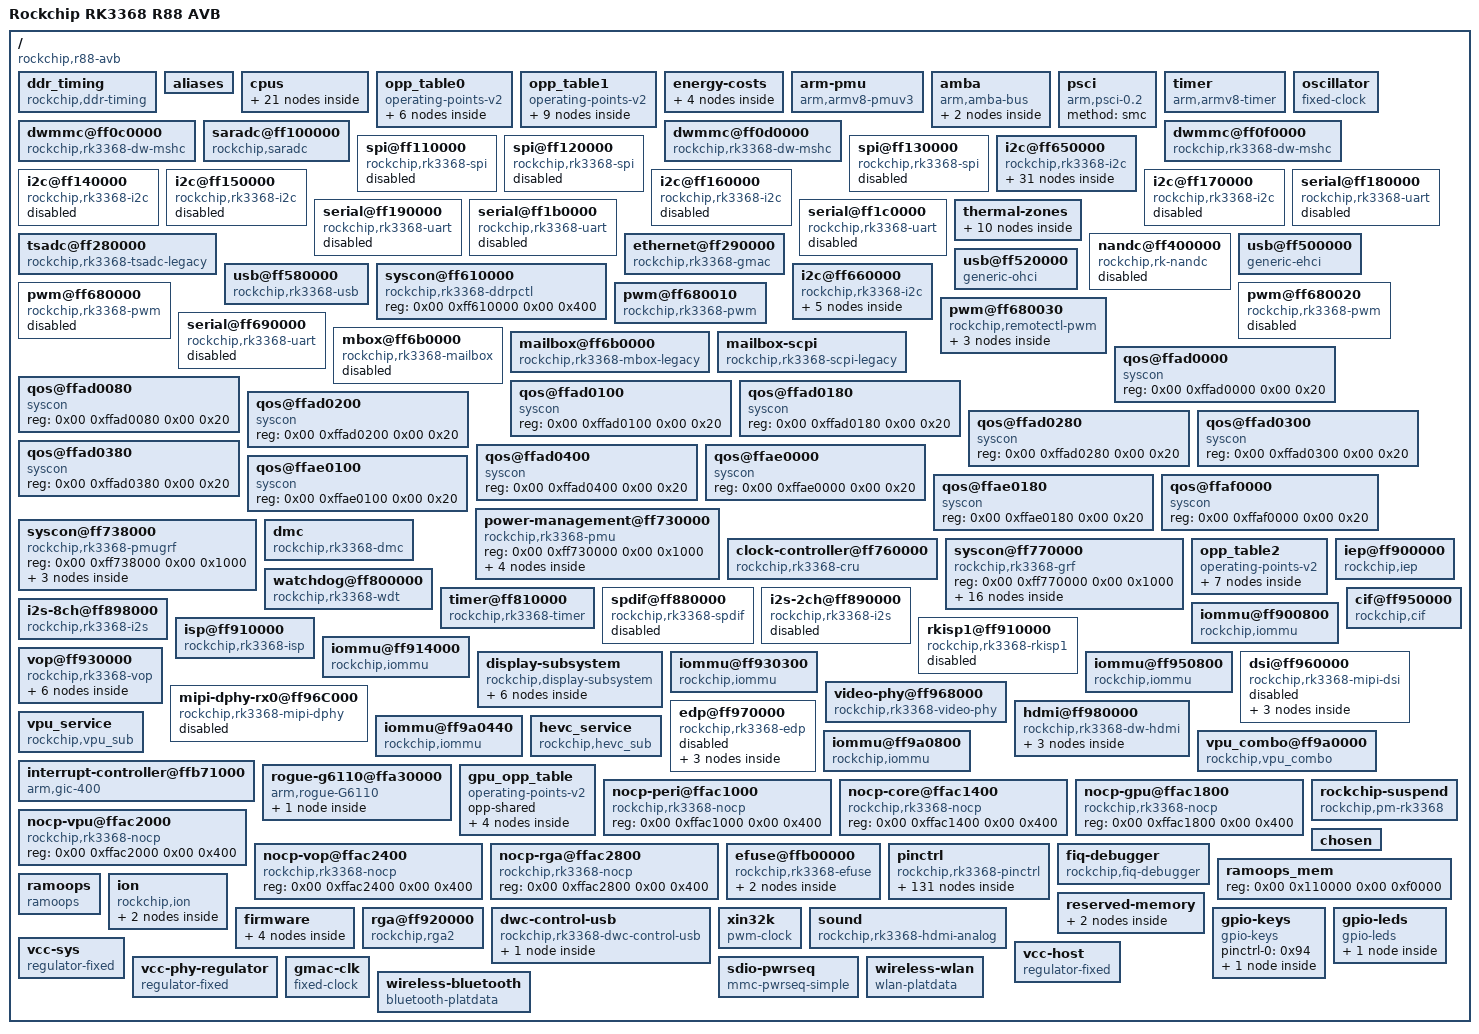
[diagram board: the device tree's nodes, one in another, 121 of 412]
/dts-v1/;

/ {
	compatible = "rockchip,r88-avb\0rockchip,rk3368";
	interrupt-parent = <0x01>;
	#address-cells = <0x02>;
	#size-cells = <0x02>;
	model = "Rockchip RK3368 R88 AVB";

	ddr_timing {
		compatible = "rockchip,ddr-timing";
		dram_spd_bin = <0x15>;
		sr_idle = <0x01>;
		pd_idle = <0x20>;
		dram_dll_disb_freq = <0x12c>;
		phy_dll_disb_freq = <0x190>;
		dram_odt_disb_freq = <0x14d>;
		phy_odt_disb_freq = <0x14d>;
		ddr3_drv = <0x00>;
		ddr3_odt = <0x40>;
		lpddr3_drv = <0x01>;
		lpddr3_odt = <0x03>;
		lpddr2_drv = <0x01>;
		phy_clk_drv = <0x0a>;
		phy_cmd_drv = <0x0c>;
		phy_dqs_drv = <0x0c>;
		phy_odt = <0x04>;
		phandle = <0x60>;
	};

	aliases {
		ethernet0 = "/ethernet@ff290000";
		i2c0 = "/i2c@ff650000";
		i2c1 = "/i2c@ff660000";
		i2c2 = "/i2c@ff140000";
		i2c3 = "/i2c@ff150000";
		i2c4 = "/i2c@ff160000";
		i2c5 = "/i2c@ff170000";
		serial0 = "/serial@ff180000";
		serial1 = "/serial@ff190000";
		serial2 = "/serial@ff690000";
		serial3 = "/serial@ff1b0000";
		serial4 = "/serial@ff1c0000";
		spi0 = "/spi@ff110000";
		spi1 = "/spi@ff120000";
		spi2 = "/spi@ff130000";
	};

	cpus {
		#address-cells = <0x02>;
		#size-cells = <0x00>;

		cpu-map {

			cluster0 {

				core0 {
					cpu = <0x02>;
				};

				core1 {
					cpu = <0x03>;
				};

				core2 {
					cpu = <0x04>;
				};

				core3 {
					cpu = <0x05>;
				};
			};

			cluster1 {

				core0 {
					cpu = <0x06>;
				};

				core1 {
					cpu = <0x07>;
				};

				core2 {
					cpu = <0x08>;
				};

				core3 {
					cpu = <0x09>;
				};
			};
		};

		cpu@0 {
			device_type = "cpu";
			compatible = "arm,cortex-a53\0arm,armv8";
			reg = <0x00 0x00>;
			enable-method = "psci";
			clocks = <0x0a 0x08>;
			next-level-cache = <0x0b>;
			operating-points-v2 = <0x0c>;
			sched-energy-costs = <0x0d 0x0e>;
			#cooling-cells = <0x02>;
			dynamic-power-coefficient = <0x95>;
			cpu-supply = <0x0f>;
			phandle = <0x02>;
		};

		cpu@1 {
			device_type = "cpu";
			compatible = "arm,cortex-a53\0arm,armv8";
			reg = <0x00 0x01>;
			enable-method = "psci";
			clocks = <0x0a 0x08>;
			next-level-cache = <0x0b>;
			operating-points-v2 = <0x0c>;
			sched-energy-costs = <0x0d 0x0e>;
			cpu-supply = <0x0f>;
			phandle = <0x03>;
		};

		cpu@2 {
			device_type = "cpu";
			compatible = "arm,cortex-a53\0arm,armv8";
			reg = <0x00 0x02>;
			enable-method = "psci";
			clocks = <0x0a 0x08>;
			next-level-cache = <0x0b>;
			operating-points-v2 = <0x0c>;
			sched-energy-costs = <0x0d 0x0e>;
			cpu-supply = <0x0f>;
			phandle = <0x04>;
		};

		cpu@3 {
			device_type = "cpu";
			compatible = "arm,cortex-a53\0arm,armv8";
			reg = <0x00 0x03>;
			enable-method = "psci";
			clocks = <0x0a 0x08>;
			next-level-cache = <0x0b>;
			operating-points-v2 = <0x0c>;
			sched-energy-costs = <0x0d 0x0e>;
			cpu-supply = <0x0f>;
			phandle = <0x05>;
		};

		cpu@100 {
			device_type = "cpu";
			compatible = "arm,cortex-a53\0arm,armv8";
			reg = <0x00 0x100>;
			enable-method = "psci";
			clocks = <0x0a 0x07>;
			next-level-cache = <0x10>;
			operating-points-v2 = <0x11>;
			sched-energy-costs = <0x12 0x13>;
			#cooling-cells = <0x02>;
			dynamic-power-coefficient = <0xa0>;
			cpu-supply = <0x0f>;
			phandle = <0x06>;
		};

		cpu@101 {
			device_type = "cpu";
			compatible = "arm,cortex-a53\0arm,armv8";
			reg = <0x00 0x101>;
			enable-method = "psci";
			clocks = <0x0a 0x07>;
			next-level-cache = <0x10>;
			operating-points-v2 = <0x11>;
			sched-energy-costs = <0x12 0x13>;
			cpu-supply = <0x0f>;
			phandle = <0x07>;
		};

		cpu@102 {
			device_type = "cpu";
			compatible = "arm,cortex-a53\0arm,armv8";
			reg = <0x00 0x102>;
			enable-method = "psci";
			clocks = <0x0a 0x07>;
			next-level-cache = <0x10>;
			operating-points-v2 = <0x11>;
			sched-energy-costs = <0x12 0x13>;
			cpu-supply = <0x0f>;
			phandle = <0x08>;
		};

		cpu@103 {
			device_type = "cpu";
			compatible = "arm,cortex-a53\0arm,armv8";
			reg = <0x00 0x103>;
			enable-method = "psci";
			clocks = <0x0a 0x07>;
			next-level-cache = <0x10>;
			operating-points-v2 = <0x11>;
			sched-energy-costs = <0x12 0x13>;
			cpu-supply = <0x0f>;
			phandle = <0x09>;
		};

		l2-cache0 {
			compatible = "cache";
			phandle = <0x0b>;
		};

		l2-cache1 {
			compatible = "cache";
			phandle = <0x10>;
		};
	};

	opp_table0 {
		compatible = "operating-points-v2";
		opp-shared;
		rockchip,leakage-voltage-sel = <0x01 0x18 0x00 0x19 0xfe 0x01>;
		nvmem-cells = <0x14>;
		nvmem-cell-names = "cpu_leakage";
		phandle = <0x0c>;

		opp-216000000 {
			opp-hz = <0x00 0xcdfe600>;
			opp-microvolt = <0xe7ef0 0xe7ef0 0x149970>;
			opp-microvolt-L0 = <0x100590 0x100590 0x149970>;
			opp-microvolt-L1 = <0xe7ef0 0xe7ef0 0x149970>;
			clock-latency-ns = <0x9c40>;
			opp-suspend;
		};

		opp-408000000 {
			opp-hz = <0x00 0x18519600>;
			opp-microvolt = <0xe7ef0 0xe7ef0 0x149970>;
			opp-microvolt-L0 = <0x100590 0x100590 0x149970>;
			opp-microvolt-L1 = <0xe7ef0 0xe7ef0 0x149970>;
			clock-latency-ns = <0x9c40>;
		};

		opp-600000000 {
			opp-hz = <0x00 0x23c34600>;
			opp-microvolt = <0xe7ef0 0xe7ef0 0x149970>;
			opp-microvolt-L0 = <0x100590 0x100590 0x149970>;
			opp-microvolt-L1 = <0xe7ef0 0xe7ef0 0x149970>;
			clock-latency-ns = <0x9c40>;
		};

		opp-816000000 {
			opp-hz = <0x00 0x30a32c00>;
			opp-microvolt = <0xfa3e8 0xfa3e8 0x149970>;
			opp-microvolt-L0 = <0x112a88 0x112a88 0x149970>;
			opp-microvolt-L1 = <0xfa3e8 0xfa3e8 0x149970>;
			clock-latency-ns = <0x9c40>;
		};

		opp-1008000000 {
			opp-hz = <0x00 0x3c14dc00>;
			opp-microvolt = <0x112a88 0x112a88 0x149970>;
			opp-microvolt-L0 = <0x12b128 0x12b128 0x149970>;
			opp-microvolt-L1 = <0x112a88 0x112a88 0x149970>;
			clock-latency-ns = <0x9c40>;
		};

		opp-1200000000 {
			opp-hz = <0x00 0x47868c00>;
			opp-microvolt = <0x12b128 0x12b128 0x149970>;
			opp-microvolt-L0 = <0x1437c8 0x1437c8 0x149970>;
			opp-microvolt-L1 = <0x12b128 0x12b128 0x149970>;
			clock-latency-ns = <0x9c40>;
		};
	};

	opp_table1 {
		compatible = "operating-points-v2";
		opp-shared;
		rockchip,avs-sclae = <0x24>;
		rockchip,leakage-scaling-sel = <0x01 0x18 0x24 0x19 0xfe 0x00>;
		clocks = <0x0a 0x01>;
		rockchip,leakage-voltage-sel = <0x01 0x18 0x00 0x19 0x32 0x01 0x33 0xfe 0x02>;
		nvmem-cells = <0x14>;
		nvmem-cell-names = "cpu_leakage";
		rockchip,avs = <0x01>;
		phandle = <0x11>;

		opp-216000000 {
			opp-hz = <0x00 0xcdfe600>;
			opp-microvolt = <0xe7ef0 0xe7ef0 0x149970>;
			opp-microvolt-L0 = <0x100590 0x100590 0x149970>;
			opp-microvolt-L1 = <0xe7ef0 0xe7ef0 0x149970>;
			opp-microvolt-L2 = <0xe7ef0 0xe7ef0 0x149970>;
			clock-latency-ns = <0x9c40>;
			opp-suspend;
		};

		opp-408000000 {
			opp-hz = <0x00 0x18519600>;
			opp-microvolt = <0xe7ef0 0xe7ef0 0x149970>;
			opp-microvolt-L0 = <0x100590 0x100590 0x149970>;
			opp-microvolt-L1 = <0xe7ef0 0xe7ef0 0x149970>;
			opp-microvolt-L2 = <0xe7ef0 0xe7ef0 0x149970>;
			clock-latency-ns = <0x9c40>;
		};

		opp-600000000 {
			opp-hz = <0x00 0x23c34600>;
			opp-microvolt = <0xe7ef0 0xe7ef0 0x149970>;
			opp-microvolt-L0 = <0x100590 0x100590 0x149970>;
			opp-microvolt-L1 = <0xe7ef0 0xe7ef0 0x149970>;
			opp-microvolt-L2 = <0xe7ef0 0xe7ef0 0x149970>;
			clock-latency-ns = <0x9c40>;
		};

		opp-816000000 {
			opp-hz = <0x00 0x30a32c00>;
			opp-microvolt = <0xee098 0xee098 0x149970>;
			opp-microvolt-L0 = <0x106738 0x106738 0x149970>;
			opp-microvolt-L1 = <0xee098 0xee098 0x149970>;
			opp-microvolt-L2 = <0xee098 0xee098 0x149970>;
			clock-latency-ns = <0x9c40>;
		};

		opp-1008000000 {
			opp-hz = <0x00 0x3c14dc00>;
			opp-microvolt = <0x100590 0x100590 0x149970>;
			opp-microvolt-L0 = <0x118c30 0x118c30 0x149970>;
			opp-microvolt-L1 = <0x100590 0x100590 0x149970>;
			opp-microvolt-L2 = <0xfa3e8 0xfa3e8 0x149970>;
			clock-latency-ns = <0x9c40>;
		};

		opp-1200000000 {
			opp-hz = <0x00 0x47868c00>;
			opp-microvolt = <0x118c30 0x118c30 0x149970>;
			opp-microvolt-L0 = <0x1312d0 0x1312d0 0x149970>;
			opp-microvolt-L1 = <0x118c30 0x118c30 0x149970>;
			opp-microvolt-L2 = <0x112a88 0x112a88 0x149970>;
			clock-latency-ns = <0x9c40>;
		};

		opp-1296000000 {
			opp-hz = <0x00 0x4d3f6400>;
			opp-microvolt = <0x12b128 0x12b128 0x149970>;
			opp-microvolt-L0 = <0x149970 0x149970 0x149970>;
			opp-microvolt-L1 = <0x12b128 0x12b128 0x149970>;
			opp-microvolt-L2 = <0x124f80 0x124f80 0x149970>;
			clock-latency-ns = <0x9c40>;
		};

		opp-1416000000 {
			opp-hz = <0x00 0x54667200>;
			opp-microvolt = <0x13d620 0x13d620 0x149970>;
			opp-microvolt-L0 = <0x149970 0x149970 0x149970>;
			opp-microvolt-L1 = <0x13d620 0x13d620 0x149970>;
			opp-microvolt-L2 = <0x137478 0x137478 0x149970>;
			clock-latency-ns = <0x9c40>;
		};

		opp-1512000000 {
			opp-hz = <0x00 0x5a1f4a00>;
			opp-microvolt = <0x149970 0x149970 0x149970>;
			opp-microvolt-L0 = <0x149970 0x149970 0x149970>;
			opp-microvolt-L1 = <0x149970 0x149970 0x149970>;
			opp-microvolt-L2 = <0x1437c8 0x1437c8 0x149970>;
			clock-latency-ns = <0x9c40>;
		};
	};

	energy-costs {

		rk3368-core-cost0 {
			busy-cost-data = <0x92 0x2c 0x114 0x48 0x196 0x63 0x228 0x93 0x2aa 0xc8 0x32c 0xff>;
			idle-cost-data = <0x06 0x06 0x00>;
			phandle = <0x0d>;
		};

		rk3368-core-cost1 {
			busy-cost-data = <0x92 0x35 0x114 0x56 0x196 0x76 0x228 0xa6 0x2aa 0xe2 0x32c 0x135 0x36e 0x173 0x3bf 0x1be 0x400 0x201>;
			idle-cost-data = <0x06 0x06 0x00>;
			phandle = <0x12>;
		};

		rk3368-cluster-cost0 {
			busy-cost-data = <0x92 0x09 0x114 0x0e 0x196 0x14 0x228 0x1d 0x2aa 0x28 0x32c 0x33>;
			idle-cost-data = <0x38 0x38 0x38>;
			phandle = <0x0e>;
		};

		rk3368-cluster-cost1 {
			busy-cost-data = <0x92 0x0b 0x114 0x11 0x196 0x18 0x228 0x21 0x2aa 0x2d 0x32c 0x3e 0x36e 0x4a 0x3bf 0x59 0x400 0x67>;
			idle-cost-data = <0x38 0x38 0x38>;
			phandle = <0x13>;
		};
	};

	arm-pmu {
		compatible = "arm,armv8-pmuv3";
		interrupts = <0x00 0x70 0x04 0x00 0x71 0x04 0x00 0x72 0x04 0x00 0x73 0x04 0x00 0x74 0x04 0x00 0x75 0x04 0x00 0x76 0x04 0x00 0x77 0x04>;
		interrupt-affinity = <0x02 0x03 0x04 0x05 0x06 0x07 0x08 0x09>;
	};

	amba {
		compatible = "arm,amba-bus";
		#address-cells = <0x02>;
		#size-cells = <0x02>;
		ranges;

		dma-controller@ff250000 {
			compatible = "arm,pl330\0arm,primecell";
			reg = <0x00 0xff250000 0x00 0x4000>;
			interrupts = <0x00 0x02 0x04 0x00 0x03 0x04>;
			#dma-cells = <0x01>;
			clocks = <0x0a 0xc3>;
			clock-names = "apb_pclk";
			arm,pl330-broken-no-flushp;
			peripherals-req-type-burst;
			phandle = <0x9c>;
		};

		dma-controller@ff600000 {
			compatible = "arm,pl330\0arm,primecell";
			reg = <0x00 0xff600000 0x00 0x4000>;
			interrupts = <0x00 0x00 0x04 0x00 0x01 0x04>;
			#dma-cells = <0x01>;
			clocks = <0x0a 0xc2>;
			clock-names = "apb_pclk";
			arm,pl330-broken-no-flushp;
			peripherals-req-type-burst;
			phandle = <0x63>;
		};
	};

	psci {
		compatible = "arm,psci-0.2";
		method = "smc";
	};

	timer {
		compatible = "arm,armv8-timer";
		interrupts = <0x01 0x0d 0xff04 0x01 0x0e 0xff04 0x01 0x0b 0xff04 0x01 0x0a 0xff04>;
	};

	oscillator {
		compatible = "fixed-clock";
		clock-frequency = <0x16e3600>;
		clock-output-names = "xin24m";
		#clock-cells = <0x00>;
		phandle = <0x9d>;
	};

	dwmmc@ff0c0000 {
		compatible = "rockchip,rk3368-dw-mshc\0rockchip,rk3288-dw-mshc";
		reg = <0x00 0xff0c0000 0x00 0x4000>;
		max-frequency = <0x8f0d180>;
		clocks = <0x0a 0x1c8 0x0a 0x44 0x0a 0x72 0x0a 0x76>;
		clock-names = "biu\0ciu\0ciu-drive\0ciu-sample";
		fifo-depth = <0x100>;
		interrupts = <0x00 0x20 0x04>;
		status = "okay";
		clock-frequency = <0x23c3460>;
		clock-freq-min-max = <0x61a80 0x23c3460>;
		supports-sd;
		cap-mmc-highspeed;
		cap-sd-highspeed;
		card-detect-delay = <0xc8>;
		disable-wp;
		num-slots = <0x01>;
		pinctrl-names = "default";
		pinctrl-0 = <0x15 0x16 0x17 0x18>;
		phandle = <0x9e>;
	};

	dwmmc@ff0d0000 {
		compatible = "rockchip,rk3368-dw-mshc\0rockchip,rk3288-dw-mshc";
		reg = <0x00 0xff0d0000 0x00 0x4000>;
		max-frequency = <0x5f5e100>;
		clocks = <0x0a 0x1c9 0x0a 0x45 0x0a 0x73 0x0a 0x77>;
		clock-names = "biu\0ciu\0ciu-drive\0ciu-sample";
		fifo-depth = <0x100>;
		interrupts = <0x00 0x21 0x04>;
		status = "okay";
		bus-width = <0x04>;
		cap-sd-highspeed;
		cap-sdio-irq;
		keep-power-in-suspend;
		mmc-pwrseq = <0x19>;
		non-removable;
		num-slots = <0x01>;
		pinctrl-names = "default";
		pinctrl-0 = <0x1a 0x1b 0x1c>;
		sd-uhs-sdr104;
		supports-sdio;
		phandle = <0x9f>;
	};

	dwmmc@ff0f0000 {
		compatible = "rockchip,rk3368-dw-mshc\0rockchip,rk3288-dw-mshc";
		reg = <0x00 0xff0f0000 0x00 0x4000>;
		max-frequency = <0x8f0d180>;
		clocks = <0x0a 0x1cb 0x0a 0x47 0x0a 0x75 0x0a 0x79>;
		clock-names = "biu\0ciu\0ciu-drive\0ciu-sample";
		fifo-depth = <0x100>;
		interrupts = <0x00 0x23 0x04>;
		status = "okay";
		bus-width = <0x08>;
		cap-mmc-highspeed;
		mmc-hs200-1_8v;
		supports-emmc;
		disable-wp;
		non-removable;
		num-slots = <0x01>;
		pinctrl-names = "default";
		pinctrl-0 = <0x1d 0x1e 0x1f>;
		phandle = <0xa0>;
	};

	saradc@ff100000 {
		compatible = "rockchip,saradc";
		reg = <0x00 0xff100000 0x00 0x100>;
		interrupts = <0x00 0x24 0x04>;
		#io-channel-cells = <0x01>;
		clocks = <0x0a 0x49 0x0a 0x15b>;
		clock-names = "saradc\0apb_pclk";
		resets = <0x0a 0x57>;
		reset-names = "saradc-apb";
		status = "okay";
		vref-supply = <0x20>;
		phandle = <0xa1>;
	};

	spi@ff110000 {
		compatible = "rockchip,rk3368-spi\0rockchip,rk3066-spi";
		reg = <0x00 0xff110000 0x00 0x1000>;
		clocks = <0x0a 0x41 0x0a 0x152>;
		clock-names = "spiclk\0apb_pclk";
		interrupts = <0x00 0x2c 0x04>;
		pinctrl-names = "default";
		pinctrl-0 = <0x21 0x22 0x23 0x24>;
		#address-cells = <0x01>;
		#size-cells = <0x00>;
		status = "disabled";
		phandle = <0xa2>;
	};

	spi@ff120000 {
		compatible = "rockchip,rk3368-spi\0rockchip,rk3066-spi";
		reg = <0x00 0xff120000 0x00 0x1000>;
		clocks = <0x0a 0x42 0x0a 0x153>;
		clock-names = "spiclk\0apb_pclk";
		interrupts = <0x00 0x2d 0x04>;
		pinctrl-names = "default";
		pinctrl-0 = <0x25 0x26 0x27 0x28>;
		#address-cells = <0x01>;
		#size-cells = <0x00>;
		status = "disabled";
		phandle = <0xa3>;
	};

	spi@ff130000 {
		compatible = "rockchip,rk3368-spi\0rockchip,rk3066-spi";
		reg = <0x00 0xff130000 0x00 0x1000>;
		clocks = <0x0a 0x43 0x0a 0x154>;
		clock-names = "spiclk\0apb_pclk";
		interrupts = <0x00 0x29 0x04>;
		pinctrl-names = "default";
		pinctrl-0 = <0x29 0x2a 0x2b 0x2c>;
		#address-cells = <0x01>;
		#size-cells = <0x00>;
		status = "disabled";
		phandle = <0xa4>;
	};

	i2c@ff650000 {
		compatible = "rockchip,rk3368-i2c\0rockchip,rk3288-i2c";
		reg = <0x00 0xff650000 0x00 0x1000>;
		clocks = <0x0a 0x14c>;
		clock-names = "i2c";
		interrupts = <0x00 0x3c 0x04>;
		pinctrl-names = "default";
		pinctrl-0 = <0x2d>;
		#address-cells = <0x01>;
		#size-cells = <0x00>;
		status = "okay";
		clock-frequency = <0x61a80>;
		phandle = <0xa5>;

		pmic@1b {
			compatible = "rockchip,rk808";
			reg = <0x1b>;
			interrupt-parent = <0x2e>;
			interrupts = <0x05 0x08>;
			pinctrl-names = "default";
			pinctrl-0 = <0x2f>;
			rockchip,system-power-controller;
			wakeup-source;
			#clock-cells = <0x01>;
			clock-output-names = "rk808-clkout1\0rk808-clkout2";
			vcc1-supply = <0x30>;
			vcc2-supply = <0x30>;
			vcc3-supply = <0x30>;
			vcc4-supply = <0x30>;
			vcc6-supply = <0x30>;
			vcc7-supply = <0x30>;
			vcc8-supply = <0x31>;
			vcc9-supply = <0x30>;
			vcc10-supply = <0x30>;
			vcc11-supply = <0x30>;
			vcc12-supply = <0x31>;
			vddio-supply = <0x31>;
			phandle = <0x97>;

			regulators {

				DCDC_REG1 {
					regulator-always-on;
					regulator-boot-on;
					regulator-min-microvolt = <0xb71b0>;
					regulator-max-microvolt = <0x149970>;
					regulator-init-microvolt = <0x100590>;
					regulator-name = "vdd_arm";
					phandle = <0x0f>;

					regulator-state-mem {
						regulator-off-in-suspend;
					};
				};

				DCDC_REG2 {
					regulator-always-on;
					regulator-boot-on;
					regulator-min-microvolt = <0xcf850>;
					regulator-max-microvolt = <0x1312d0>;
					regulator-name = "vdd_gpu";
					regulator-ramp-delay = <0x1770>;
					phandle = <0x62>;

					regulator-state-mem {
						regulator-on-in-suspend;
						regulator-suspend-microvolt = <0xf4240>;
					};
				};

				DCDC_REG3 {
					regulator-always-on;
					regulator-boot-on;
					regulator-name = "vcc_ddr";
					phandle = <0xa6>;

					regulator-state-mem {
						regulator-on-in-suspend;
					};
				};

				DCDC_REG4 {
					regulator-always-on;
					regulator-boot-on;
					regulator-min-microvolt = <0x325aa0>;
					regulator-max-microvolt = <0x325aa0>;
					regulator-name = "vcc_io";
					phandle = <0x31>;

					regulator-state-mem {
						regulator-on-in-suspend;
						regulator-suspend-microvolt = <0x325aa0>;
					};
				};

				LDO_REG1 {
					regulator-always-on;
					regulator-boot-on;
					regulator-min-microvolt = <0x1b7740>;
					regulator-max-microvolt = <0x1b7740>;
					regulator-name = "vcc18_flash";
					phandle = <0x57>;

					regulator-state-mem {
						regulator-on-in-suspend;
						regulator-suspend-microvolt = <0x1b7740>;
					};
				};

				LDO_REG2 {
					regulator-always-on;
					regulator-boot-on;
					regulator-min-microvolt = <0x325aa0>;
					regulator-max-microvolt = <0x325aa0>;
					regulator-name = "vcca_33";
					phandle = <0xa7>;

					regulator-state-mem {
						regulator-off-in-suspend;
					};
				};

				LDO_REG3 {
					regulator-always-on;
					regulator-boot-on;
					regulator-min-microvolt = <0xf4240>;
					regulator-max-microvolt = <0xf4240>;
					regulator-name = "vdd_10";
					phandle = <0xa8>;

					regulator-state-mem {
						regulator-on-in-suspend;
						regulator-suspend-microvolt = <0xf4240>;
					};
				};

				LDO_REG4 {
					regulator-always-on;
					regulator-boot-on;
					regulator-min-microvolt = <0x1b7740>;
					regulator-max-microvolt = <0x1b7740>;
					regulator-name = "vcca_18";
					phandle = <0xa9>;

					regulator-state-mem {
						regulator-on-in-suspend;
						regulator-suspend-microvolt = <0x1b7740>;
					};
				};

				LDO_REG5 {
					regulator-always-on;
					regulator-boot-on;
					regulator-min-microvolt = <0x1b7740>;
					regulator-max-microvolt = <0x325aa0>;
					regulator-name = "vccio_sd";
					phandle = <0x58>;

					regulator-state-mem {
						regulator-on-in-suspend;
						regulator-suspend-microvolt = <0x325aa0>;
					};
				};

				LDO_REG6 {
					regulator-always-on;
					regulator-boot-on;
					regulator-min-microvolt = <0xf4240>;
					regulator-max-microvolt = <0xf4240>;
					regulator-name = "vdd10_lcd";
					phandle = <0xaa>;

					regulator-state-mem {
						regulator-on-in-suspend;
						regulator-suspend-microvolt = <0xf4240>;
					};
				};

				LDO_REG7 {
					regulator-always-on;
					regulator-boot-on;
					regulator-min-microvolt = <0x1b7740>;
					regulator-max-microvolt = <0x1b7740>;
					regulator-name = "vcc_18";
					phandle = <0x20>;

					regulator-state-mem {
						regulator-on-in-suspend;
						regulator-suspend-microvolt = <0x1b7740>;
					};
				};

				LDO_REG8 {
					regulator-always-on;
					regulator-boot-on;
					regulator-min-microvolt = <0x1b7740>;
					regulator-max-microvolt = <0x1b7740>;
					regulator-name = "vcc18_lcd";
					phandle = <0xab>;

					regulator-state-mem {
						regulator-on-in-suspend;
						regulator-suspend-microvolt = <0x1b7740>;
					};
				};

				SWITCH_REG1 {
					regulator-always-on;
					regulator-boot-on;
					regulator-name = "vcc_sd";
					phandle = <0xac>;

					regulator-state-mem {
						regulator-on-in-suspend;
					};
				};

				SWITCH_REG2 {
					regulator-always-on;
					regulator-boot-on;
					regulator-name = "vcc_lan";
					phandle = <0xad>;

					regulator-state-mem {
						regulator-on-in-suspend;
					};
				};
			};
		};

		hym8563@51 {
			compatible = "haoyu,hym8563";
			reg = <0x51>;
			#clock-cells = <0x00>;
			clock-frequency = <0x8000>;
			clock-output-names = "xin32k";
			phandle = <0xae>;
		};
	};

	i2c@ff140000 {
		compatible = "rockchip,rk3368-i2c\0rockchip,rk3288-i2c";
		reg = <0x00 0xff140000 0x00 0x1000>;
		interrupts = <0x00 0x3e 0x04>;
		#address-cells = <0x01>;
		#size-cells = <0x00>;
		clock-names = "i2c";
		clocks = <0x0a 0x14e>;
		pinctrl-names = "default";
		pinctrl-0 = <0x32>;
		status = "disabled";
		phandle = <0xaf>;
	};

	i2c@ff150000 {
		compatible = "rockchip,rk3368-i2c\0rockchip,rk3288-i2c";
		reg = <0x00 0xff150000 0x00 0x1000>;
		interrupts = <0x00 0x3f 0x04>;
		#address-cells = <0x01>;
		#size-cells = <0x00>;
		clock-names = "i2c";
		clocks = <0x0a 0x14f>;
		pinctrl-names = "default";
		pinctrl-0 = <0x33>;
		status = "disabled";
		phandle = <0xb0>;
	};

	i2c@ff160000 {
		compatible = "rockchip,rk3368-i2c\0rockchip,rk3288-i2c";
		reg = <0x00 0xff160000 0x00 0x1000>;
		interrupts = <0x00 0x40 0x04>;
		#address-cells = <0x01>;
		#size-cells = <0x00>;
		clock-names = "i2c";
		clocks = <0x0a 0x150>;
		pinctrl-names = "default";
		pinctrl-0 = <0x34>;
		status = "disabled";
		phandle = <0xb1>;
	};

	i2c@ff170000 {
		compatible = "rockchip,rk3368-i2c\0rockchip,rk3288-i2c";
		reg = <0x00 0xff170000 0x00 0x1000>;
		interrupts = <0x00 0x41 0x04>;
		#address-cells = <0x01>;
		#size-cells = <0x00>;
		clock-names = "i2c";
		clocks = <0x0a 0x151>;
		pinctrl-names = "default";
		pinctrl-0 = <0x35>;
		status = "disabled";
		phandle = <0xb2>;
	};

	serial@ff180000 {
		compatible = "rockchip,rk3368-uart\0snps,dw-apb-uart";
		reg = <0x00 0xff180000 0x00 0x100>;
		clock-frequency = <0x16e3600>;
		clocks = <0x0a 0x4d 0x0a 0x155>;
		clock-names = "baudclk\0apb_pclk";
		interrupts = <0x00 0x37 0x04>;
		reg-shift = <0x02>;
		reg-io-width = <0x04>;
		status = "disabled";
		phandle = <0xb3>;
	};

	serial@ff190000 {
		compatible = "rockchip,rk3368-uart\0snps,dw-apb-uart";
		reg = <0x00 0xff190000 0x00 0x100>;
		clock-frequency = <0x16e3600>;
		clocks = <0x0a 0x4e 0x0a 0x156>;
		clock-names = "baudclk\0apb_pclk";
		interrupts = <0x00 0x38 0x04>;
		reg-shift = <0x02>;
		reg-io-width = <0x04>;
		status = "disabled";
		phandle = <0xb4>;
	};

	serial@ff1b0000 {
		compatible = "rockchip,rk3368-uart\0snps,dw-apb-uart";
		reg = <0x00 0xff1b0000 0x00 0x100>;
		clock-frequency = <0x16e3600>;
		clocks = <0x0a 0x50 0x0a 0x158>;
		clock-names = "baudclk\0apb_pclk";
		interrupts = <0x00 0x3a 0x04>;
		reg-shift = <0x02>;
		reg-io-width = <0x04>;
		status = "disabled";
		phandle = <0xb5>;
	};

	serial@ff1c0000 {
		compatible = "rockchip,rk3368-uart\0snps,dw-apb-uart";
		reg = <0x00 0xff1c0000 0x00 0x100>;
		clock-frequency = <0x16e3600>;
		clocks = <0x0a 0x51 0x0a 0x159>;
		clock-names = "baudclk\0apb_pclk";
		interrupts = <0x00 0x3b 0x04>;
		reg-shift = <0x02>;
		reg-io-width = <0x04>;
		status = "disabled";
		phandle = <0xb6>;
	};

	thermal-zones {
		phandle = <0xb7>;

		soc-thermal {
			polling-delay-passive = <0xc8>;
			polling-delay = <0xc8>;
			sustainable-power = <0x258>;
			thermal-sensors = <0x36 0x00>;
			phandle = <0xb8>;

			trips {

				trip-point-0 {
					temperature = <0x11170>;
					hysteresis = <0x7d0>;
					type = "passive";
					phandle = <0xb9>;
				};

				trip-point-1 {
					temperature = <0x13880>;
					hysteresis = <0x7d0>;
					type = "passive";
					phandle = <0x37>;
				};

				soc-crit {
					temperature = <0x1c138>;
					hysteresis = <0x7d0>;
					type = "critical";
					phandle = <0xba>;
				};
			};

			cooling-maps {

				map0 {
					trip = <0x37>;
					cooling-device = <0x02 0xffffffff 0xffffffff>;
					contribution = <0x400>;
				};

				map1 {
					trip = <0x37>;
					cooling-device = <0x06 0xffffffff 0xffffffff>;
					contribution = <0x400>;
				};

				map2 {
					trip = <0x37>;
					cooling-device = <0x38 0xffffffff 0xffffffff>;
					contribution = <0x400>;
				};
			};
		};

		gpu-thermal {
			polling-delay-passive = <0xc8>;
			polling-delay = <0xc8>;
			thermal-sensors = <0x36 0x01>;
			phandle = <0xbb>;
		};
	};

	tsadc@ff280000 {
		compatible = "rockchip,rk3368-tsadc-legacy";
		reg = <0x00 0xff280000 0x00 0x100>;
		interrupts = <0x00 0x25 0x04>;
		clocks = <0x0a 0x48 0x0a 0x15a>;
		clock-names = "tsadc\0apb_pclk";
		clock-frequency = <0x8000>;
		resets = <0x0a 0x9f>;
		reset-names = "tsadc-apb";
		nvmem-cells = <0x39>;
		nvmem-cell-names = "temp_adjust";
		#thermal-sensor-cells = <0x01>;
		hw-shut-temp = <0x17318>;
		latency-bound = <0xc350>;
		status = "okay";
		tsadc-supply = <0x0f>;
		phandle = <0x36>;
	};

	ethernet@ff290000 {
		compatible = "rockchip,rk3368-gmac";
		reg = <0x00 0xff290000 0x00 0x10000>;
		interrupts = <0x00 0x1b 0x04>;
		interrupt-names = "macirq";
		rockchip,grf = <0x3a>;
		clocks = <0x0a 0x7f 0x0a 0x66 0x0a 0x67 0x0a 0x63 0x0a 0x80 0x0a 0xc5 0x0a 0x15d>;
		clock-names = "stmmaceth\0mac_clk_rx\0mac_clk_tx\0clk_mac_ref\0clk_mac_refout\0aclk_mac\0pclk_mac";
		status = "ok";
		phy-supply = <0x3b>;
		phy-mode = "rmii";
		clock_in_out = "output";
		snps,reset-gpio = <0x3c 0x0c 0x01>;
		snps,reset-active-low;
		snps,reset-delays-us = <0x00 0xc350 0xc350>;
		pinctrl-names = "default";
		pinctrl-0 = <0x3d>;
		tx_delay = <0x30>;
		rx_delay = <0x10>;
		phandle = <0xbc>;
	};

	nandc@ff400000 {
		compatible = "rockchip,rk-nandc";
		reg = <0x00 0xff400000 0x00 0x4000>;
		interrupts = <0x00 0x26 0x04>;
		nandc_id = <0x00>;
		clocks = <0x0a 0x4b 0x0a 0x1c5>;
		clock-names = "clk_nandc\0hclk_nandc";
		status = "disabled";
		phandle = <0xbd>;
	};

	usb@ff500000 {
		compatible = "generic-ehci";
		reg = <0x00 0xff500000 0x00 0x20000>;
		interrupts = <0x00 0x18 0x04>;
		clocks = <0x0a 0x1c2 0x3e>;
		clock-names = "usbhost\0utmi";
		phys = <0x3f>;
		phy-names = "usb";
		status = "okay";
		phandle = <0xbe>;
	};

	usb@ff520000 {
		compatible = "generic-ohci";
		reg = <0x00 0xff520000 0x00 0x20000>;
		interrupts = <0x00 0x19 0x04>;
		clocks = <0x0a 0x1c2 0x3e>;
		clock-names = "usbhost\0utmi";
		phys = <0x3f>;
		phy-names = "usb";
		status = "okay";
		phandle = <0xbf>;
	};

	usb@ff580000 {
		compatible = "rockchip,rk3368-usb";
		reg = <0x00 0xff580000 0x00 0x40000>;
		interrupts = <0x00 0x17 0x04>;
		clocks = <0x0a 0x5d 0x0a 0x1c1>;
		clock-names = "sclk_otgphy0\0otg";
		dr_mode = "otg";
		g-np-tx-fifo-size = <0x10>;
		g-rx-fifo-size = <0x118>;
		g-tx-fifo-size = <0x100 0x80 0x80 0x40 0x20 0x10>;
		g-use-dma;
		phys = <0x40>;
		phy-names = "usb2-phy";
		status = "okay";
		resets = <0x0a 0x84 0x0a 0x85 0x0a 0x86>;
		reset-names = "otg_ahb\0otg_phy\0otg_controller";
		rockchip,usb-mode = <0x00>;
		phandle = <0xc0>;
	};

	syscon@ff610000 {
		compatible = "rockchip,rk3368-ddrpctl\0syscon";
		reg = <0x00 0xff610000 0x00 0x400>;
		phandle = <0xc1>;
	};

	i2c@ff660000 {
		compatible = "rockchip,rk3368-i2c\0rockchip,rk3288-i2c";
		reg = <0x00 0xff660000 0x00 0x1000>;
		interrupts = <0x00 0x3d 0x04>;
		#address-cells = <0x01>;
		#size-cells = <0x00>;
		clock-names = "i2c";
		clocks = <0x0a 0x14d>;
		pinctrl-names = "default";
		pinctrl-0 = <0x41>;
		status = "okay";
		phandle = <0xc2>;

		rk1000-ctl@40 {
			compatible = "rockchip,rk1000-ctl";
			status = "okay";
			reg = <0x40>;
			reset-gpios = <0x2e 0x01 0x01>;
			clocks = <0x0a 0x71>;
			clock-names = "mclk";
			pinctrl-names = "default";
			pinctrl-0 = <0x42>;
			phandle = <0x43>;
		};

		rk1000-tve@42 {
			status = "okay";
			compatible = "rockchip,rk1000-tve";
			reg = <0x42>;
			rockchip,ctl = <0x43>;
			#address-cells = <0x01>;
			#size-cells = <0x00>;

			port@0 {
				reg = <0x00>;

				endpoint {
					remote-endpoint = <0x44>;
					phandle = <0x5e>;
				};
			};
		};

		rk1000-codec@60 {
			compatible = "rockchip,rk1000-codec";
			reg = <0x60>;
			#sound-dai-cells = <0x00>;
			rockchip,ctl = <0x43>;
			rockchip,spk-en-gpio = <0x3c 0x1f 0x01>;
			rockchip,pa-en-time-ms = <0x1388>;
			status = "okay";
			phandle = <0x92>;
		};
	};

	pwm@ff680000 {
		compatible = "rockchip,rk3368-pwm\0rockchip,rk3288-pwm";
		reg = <0x00 0xff680000 0x00 0x10>;
		#pwm-cells = <0x03>;
		pinctrl-names = "active";
		pinctrl-0 = <0x45>;
		clocks = <0x0a 0x15f>;
		clock-names = "pwm";
		status = "disabled";
		phandle = <0xc3>;
	};

	pwm@ff680010 {
		compatible = "rockchip,rk3368-pwm\0rockchip,rk3288-pwm";
		reg = <0x00 0xff680010 0x00 0x10>;
		#pwm-cells = <0x03>;
		pinctrl-names = "active";
		pinctrl-0 = <0x46>;
		clocks = <0x0a 0x15f>;
		clock-names = "pwm";
		status = "okay";
		phandle = <0x90>;
	};

	pwm@ff680020 {
		compatible = "rockchip,rk3368-pwm\0rockchip,rk3288-pwm";
		reg = <0x00 0xff680020 0x00 0x10>;
		#pwm-cells = <0x03>;
		clocks = <0x0a 0x15f>;
		clock-names = "pwm";
		status = "disabled";
		phandle = <0xc4>;
	};

	pwm@ff680030 {
		compatible = "rockchip,remotectl-pwm";
		reg = <0x00 0xff680030 0x00 0x10>;
		#pwm-cells = <0x03>;
		pinctrl-names = "default";
		pinctrl-0 = <0x47>;
		clocks = <0x0a 0x15f>;
		clock-names = "pwm";
		status = "okay";
		interrupts = <0x00 0x4e 0x04>;
		remote_pwm_id = <0x03>;
		handle_cpu_id = <0x01>;
		remote_support_psci = <0x01>;
		phandle = <0xc5>;

		ir_key1 {
			rockchip,usercode = <0x4040>;
			rockchip,key_table = <0xf2 0xe8 0xba 0x9e 0xf4 0x67 0xf1 0x6c 0xef 0x69 0xee 0x6a 0xbd 0x66 0xea 0x73 0xe3 0x72 0xe2 0xd9 0xb2 0x74 0xbc 0x71 0xec 0x8b 0xbf 0x190 0xe0 0x191 0xe1 0x192 0xe9 0xb7 0xe6 0xf8 0xe8 0xb9 0xe7 0xba 0xf0 0x184 0xbe 0x175>;
		};

		ir_key2 {
			rockchip,usercode = <0xff00>;
			rockchip,key_table = <0xf9 0x66 0xbf 0x9e 0xfb 0x8b 0xaa 0xe8 0xb9 0x67 0xe9 0x6c 0xb8 0x69 0xea 0x6a 0xeb 0x72 0xef 0x73 0xf7 0x71 0xe7 0x74 0xfc 0x74 0xa9 0x72 0xa8 0x72 0xe0 0x72 0xa5 0x72 0xab 0xb7 0xb7 0x184 0xe8 0x184 0xf8 0xb8 0xaf 0xb9 0xed 0x72 0xee 0xba 0xb3 0x72 0xb3 0x72 0xf1 0x72 0xf2 0x72 0xf3 0xd9 0xb4 0x72 0xbe 0xd9>;
		};

		ir_key3 {
			rockchip,usercode = <0x1dcc>;
			rockchip,key_table = <0xee 0xe8 0xf0 0x9e 0xf8 0x67 0xbb 0x6c 0xef 0x69 0xed 0x6a 0xfc 0x66 0xf1 0x73 0xfd 0x72 0xb7 0xd9 0xff 0x74 0xf3 0x71 0xbf 0x8b 0xf9 0x191 0xf5 0x192 0xb3 0x184 0xbe 0x02 0xba 0x03 0xb2 0x04 0xbd 0x05 0xf9 0x06 0xb1 0x07 0xfc 0x08 0xf8 0x09 0xb0 0x0a 0xb6 0x0b 0xb5 0x0e>;
		};
	};

	serial@ff690000 {
		compatible = "rockchip,rk3368-uart\0snps,dw-apb-uart";
		reg = <0x00 0xff690000 0x00 0x100>;
		clocks = <0x0a 0x4f 0x0a 0x157>;
		clock-names = "baudclk\0apb_pclk";
		interrupts = <0x00 0x39 0x04>;
		pinctrl-names = "default";
		pinctrl-0 = <0x48>;
		reg-shift = <0x02>;
		reg-io-width = <0x04>;
		status = "disabled";
		phandle = <0xc6>;
	};

	mbox@ff6b0000 {
		compatible = "rockchip,rk3368-mailbox";
		reg = <0x00 0xff6b0000 0x00 0x1000>;
		interrupts = <0x00 0x92 0x04 0x00 0x93 0x04 0x00 0x94 0x04 0x00 0x95 0x04>;
		clocks = <0x0a 0x145>;
		clock-names = "pclk_mailbox";
		#mbox-cells = <0x01>;
		status = "disabled";
		phandle = <0xc7>;
	};

	mailbox@ff6b0000 {
		compatible = "rockchip,rk3368-mbox-legacy";
		reg = <0x00 0xff6b0000 0x00 0x1000 0x00 0xff8cf000 0x00 0x1000>;
		interrupts = <0x00 0x92 0x04 0x00 0x93 0x04 0x00 0x94 0x04 0x00 0x95 0x04>;
		clocks = <0x0a 0x145>;
		clock-names = "pclk_mailbox";
		#mbox-cells = <0x01>;
		status = "okay";
		phandle = <0x49>;
	};

	mailbox-scpi {
		compatible = "rockchip,rk3368-scpi-legacy";
		mboxes = <0x49 0x00 0x49 0x01 0x49 0x02>;
		chan-nums = <0x03>;
		status = "okay";
		phandle = <0xc8>;
	};

	qos@ffad0000 {
		compatible = "syscon";
		reg = <0x00 0xffad0000 0x00 0x20>;
		phandle = <0x4a>;
	};

	qos@ffad0080 {
		compatible = "syscon";
		reg = <0x00 0xffad0080 0x00 0x20>;
		phandle = <0x4b>;
	};

	qos@ffad0100 {
		compatible = "syscon";
		reg = <0x00 0xffad0100 0x00 0x20>;
		phandle = <0x4c>;
	};

	qos@ffad0180 {
		compatible = "syscon";
		reg = <0x00 0xffad0180 0x00 0x20>;
		phandle = <0x4d>;
	};

	qos@ffad0200 {
		compatible = "syscon";
		reg = <0x00 0xffad0200 0x00 0x20>;
		phandle = <0x4e>;
	};

	qos@ffad0280 {
		compatible = "syscon";
		reg = <0x00 0xffad0280 0x00 0x20>;
		phandle = <0x4f>;
	};

	qos@ffad0300 {
		compatible = "syscon";
		reg = <0x00 0xffad0300 0x00 0x20>;
		phandle = <0x50>;
	};

	qos@ffad0380 {
		compatible = "syscon";
		reg = <0x00 0xffad0380 0x00 0x20>;
		phandle = <0x51>;
	};

	qos@ffad0400 {
		compatible = "syscon";
		reg = <0x00 0xffad0400 0x00 0x20>;
		phandle = <0x52>;
	};

	qos@ffae0000 {
		compatible = "syscon";
		reg = <0x00 0xffae0000 0x00 0x20>;
		phandle = <0x53>;
	};

	qos@ffae0100 {
		compatible = "syscon";
		reg = <0x00 0xffae0100 0x00 0x20>;
		phandle = <0x54>;
	};

	qos@ffae0180 {
		compatible = "syscon";
		reg = <0x00 0xffae0180 0x00 0x20>;
		phandle = <0x55>;
	};

	qos@ffaf0000 {
		compatible = "syscon";
		reg = <0x00 0xffaf0000 0x00 0x20>;
		phandle = <0x56>;
	};

	power-management@ff730000 {
		compatible = "rockchip,rk3368-pmu\0syscon\0simple-mfd";
		reg = <0x00 0xff730000 0x00 0x1000>;
		phandle = <0xc9>;

		power-controller {
			compatible = "rockchip,rk3368-power-controller";
			#power-domain-cells = <0x01>;
			#address-cells = <0x01>;
			#size-cells = <0x00>;
			phandle = <0x67>;

			pd_vio@12 {
				reg = <0x0c>;
				clocks = <0x0a 0xca 0x0a 0xcd 0x0a 0xcc 0x0a 0xc8 0x0a 0xc6 0x0a 0xc7 0x0a 0xbe 0x0a 0x1d4 0x0a 0x1d5 0x0a 0x1d6 0x0a 0x1d9 0x0a 0x1d1 0x0a 0x1db 0x0a 0x163 0x0a 0x168 0x0a 0x167 0x0a 0x16e 0x0a 0x16f 0x0a 0x171 0x0a 0x172 0x0a 0x166 0x0a 0x164 0x0a 0x64 0x0a 0x68 0x0a 0x69 0x0a 0x6c 0x0a 0x6b 0x0a 0x6a 0x0a 0x6e 0x0a 0x6d>;
				pm_qos = <0x4a 0x4b 0x4c 0x4d 0x4e 0x4f 0x50 0x51 0x52>;
			};

			pd_video@14 {
				reg = <0x0e>;
				clocks = <0x0a 0xd0 0x0a 0x1dc 0x0a 0x6f 0x0a 0x70>;
				pm_qos = <0x53 0x54 0x55>;
			};

			pd_gpu_1@16 {
				reg = <0x10>;
				clocks = <0x0a 0xc1 0x0a 0xc0 0x0a 0x40>;
				pm_qos = <0x56>;
			};
		};
	};

	syscon@ff738000 {
		compatible = "rockchip,rk3368-pmugrf\0syscon\0simple-mfd";
		reg = <0x00 0xff738000 0x00 0x1000>;
		phandle = <0x88>;

		io-domains {
			compatible = "rockchip,rk3368-pmu-io-voltage-domain";
			status = "okay";
			pmu-supply = <0x31>;
			vop-supply = <0x31>;
			phandle = <0xca>;
		};

		pvtm-clock {
			compatible = "rockchip,rk3368-pvtm-clock";
			#clock-cells = <0x00>;
			clocks = <0x0a 0x7d>;
			clock-names = "pvtm_pmu_clk";
			clock-output-names = "xin32k_pvtm";
			status = "okay";
			phandle = <0xcb>;
		};

		reboot-mode {
			compatible = "syscon-reboot-mode";
			offset = <0x200>;
			mode-normal = <0x5242c300>;
			mode-recovery = <0x5242c303>;
			mode-bootloader = <0x5242c309>;
			mode-loader = <0x5242c301>;
		};
	};

	clock-controller@ff760000 {
		compatible = "rockchip,rk3368-cru";
		reg = <0x00 0xff760000 0x00 0x1000>;
		rockchip,grf = <0x3a>;
		#clock-cells = <0x01>;
		#reset-cells = <0x01>;
		assigned-clocks = <0x0a 0x08 0x0a 0x07 0x0a 0x05 0x0a 0x04 0x0a 0xd1 0x0a 0xd2 0x0a 0x1dd 0x0a 0x1de 0x0a 0x16a 0x0a 0x16b 0x0a 0xd3>;
		assigned-clock-rates = <0x30a32c00 0x30a32c00 0x22551000 0x17d78400 0x11e1a300 0x11e1a300 0x8f0d180 0x8f0d180 0x47868c0 0x47868c0 0x22551000>;
		phandle = <0x0a>;
	};

	syscon@ff770000 {
		compatible = "rockchip,rk3368-grf\0syscon\0simple-mfd";
		reg = <0x00 0xff770000 0x00 0x1000>;
		#address-cells = <0x01>;
		#size-cells = <0x01>;
		phandle = <0x3a>;

		edp-phy {
			compatible = "rockchip,rk3368-dp-phy";
			clocks = <0x0a 0x68>;
			clock-names = "24m";
			resets = <0x0a 0x6f>;
			reset-names = "edp_24m";
			#phy-cells = <0x00>;
			status = "disabled";
			phandle = <0x7f>;
		};

		io-domains {
			compatible = "rockchip,rk3368-io-voltage-domain";
			status = "ok";
			dvp-supply = <0x20>;
			flash0-supply = <0x57>;
			sdcard-supply = <0x58>;
			audio-supply = <0x31>;
			gpio30-supply = <0x31>;
			gpio1830-supply = <0x31>;
			wifi-supply = <0x31>;
			phandle = <0xcc>;
		};

		lvds {
			compatible = "rockchip,rk3368-lvds";
			phys = <0x59>;
			phy-names = "phy";
			status = "disabled";
			phandle = <0xcd>;

			ports {
				#address-cells = <0x01>;
				#size-cells = <0x00>;

				port@0 {
					reg = <0x00>;

					endpoint {
						remote-endpoint = <0x5a>;
						phandle = <0x77>;
					};
				};
			};
		};

		rgb {
			compatible = "rockchip,rk3368-rgb";
			phys = <0x59>;
			phy-names = "phy";
			pinctrl-names = "default\0sleep";
			pinctrl-0 = <0x5b>;
			pinctrl-1 = <0x5c>;
			status = "okay";
			phandle = <0xce>;

			ports {
				#address-cells = <0x01>;
				#size-cells = <0x00>;

				port@0 {
					reg = <0x00>;

					endpoint {
						remote-endpoint = <0x5d>;
						phandle = <0x78>;
					};
				};

				port@1 {
					reg = <0x01>;

					endpoint {
						remote-endpoint = <0x5e>;
						phandle = <0x44>;
					};
				};
			};
		};

		usb2-phy@700 {
			compatible = "rockchip,rk3368-usb2phy";
			reg = <0x700 0x2c>;
			clocks = <0x0a 0x5d>;
			clock-names = "phyclk";
			#clock-cells = <0x00>;
			clock-output-names = "usbotg_out";
			assigned-clocks = <0x0a 0x7a>;
			assigned-clock-parents = <0x3e>;
			status = "okay";
			phandle = <0x3e>;

			otg-port {
				#phy-cells = <0x00>;
				interrupts = <0x00 0x5e 0x04 0x00 0x5d 0x04 0x00 0x5f 0x04>;
				interrupt-names = "otg-bvalid\0otg-id\0linestate";
				status = "disabled";
				phandle = <0x40>;
			};

			host-port {
				#phy-cells = <0x00>;
				interrupts = <0x00 0x60 0x04>;
				interrupt-names = "linestate";
				status = "okay";
				phandle = <0x3f>;
			};
		};

		dfi {
			compatible = "rockchip,rk3368-dfi";
			status = "okay";
			phandle = <0x5f>;
		};
	};

	dmc {
		compatible = "rockchip,rk3368-dmc";
		devfreq-events = <0x5f>;
		clocks = <0x0a 0x8b 0x0a 0x16d 0x0a 0x16c>;
		clock-names = "dmc_clk\0pclk_phy\0pclk_upctl";
		ddr_timing = <0x60>;
		upthreshold = <0x32>;
		downdifferential = <0x14>;
		operating-points-v2 = <0x61>;
		vop-dclk-mode = <0x00>;
		system-status-freq = <0x01 0x80e80 0x08 0x927c0 0x02 0x2ee00 0x20 0x61a80 0x10 0xc3500 0x2000 0xc3500 0x1000 0x61a80 0xc00 0x61a80 0x4000 0x61a80>;
		auto-min-freq = <0x60ae0>;
		auto-freq-en = <0x00>;
		status = "okay";
		center-supply = <0x62>;
		phandle = <0x72>;
	};

	opp_table2 {
		compatible = "operating-points-v2";
		phandle = <0x61>;

		opp-192000000 {
			opp-hz = <0x00 0xb71b000>;
			opp-microvolt = <0x10c8e0>;
		};

		opp-240000000 {
			opp-hz = <0x00 0xe4e1c00>;
			opp-microvolt = <0x10c8e0>;
		};

		opp-300000000 {
			opp-hz = <0x00 0x11e1a300>;
			opp-microvolt = <0x10c8e0>;
		};

		opp-396000000 {
			opp-hz = <0x00 0x179a7b00>;
			opp-microvolt = <0x10c8e0>;
		};

		opp-528000000 {
			opp-hz = <0x00 0x1f78a400>;
			opp-microvolt = <0x10c8e0>;
		};

		opp-600000000 {
			opp-hz = <0x00 0x23c34600>;
			opp-microvolt = <0x10c8e0>;
		};

		opp-800000000 {
			opp-hz = <0x00 0x2faf0800>;
			opp-microvolt = <0x11edd8>;
		};
	};

	watchdog@ff800000 {
		compatible = "rockchip,rk3368-wdt\0snps,dw-wdt";
		reg = <0x00 0xff800000 0x00 0x100>;
		clocks = <0x0a 0x170>;
		interrupts = <0x00 0x4f 0x04>;
		status = "okay";
		phandle = <0xcf>;
	};

	timer@ff810000 {
		compatible = "rockchip,rk3368-timer\0rockchip,rk3288-timer";
		reg = <0x00 0xff810000 0x00 0x20>;
		interrupts = <0x00 0x42 0x04>;
	};

	spdif@ff880000 {
		compatible = "rockchip,rk3368-spdif";
		reg = <0x00 0xff880000 0x00 0x1000>;
		interrupts = <0x00 0x36 0x04>;
		dmas = <0x63 0x03>;
		dma-names = "tx";
		clock-names = "mclk\0hclk";
		clocks = <0x0a 0x53 0x0a 0x1d0>;
		pinctrl-names = "default";
		pinctrl-0 = <0x64>;
		status = "disabled";
		phandle = <0xd0>;
	};

	i2s-2ch@ff890000 {
		compatible = "rockchip,rk3368-i2s\0rockchip,rk3066-i2s";
		reg = <0x00 0xff890000 0x00 0x1000>;
		interrupts = <0x00 0x28 0x04>;
		dmas = <0x63 0x06 0x63 0x07>;
		dma-names = "tx\0rx";
		clock-names = "i2s_clk\0i2s_hclk";
		clocks = <0x0a 0x54 0x0a 0x1ce>;
		resets = <0x0a 0x19>;
		reset-names = "reset-m";
		status = "disabled";
		phandle = <0xd1>;
	};

	i2s-8ch@ff898000 {
		compatible = "rockchip,rk3368-i2s\0rockchip,rk3066-i2s";
		reg = <0x00 0xff898000 0x00 0x1000>;
		interrupts = <0x00 0x35 0x04>;
		dmas = <0x63 0x00 0x63 0x01>;
		dma-names = "tx\0rx";
		clock-names = "i2s_clk\0i2s_hclk";
		clocks = <0x0a 0x52 0x0a 0x1cf>;
		resets = <0x0a 0x17>;
		reset-names = "reset-m";
		pinctrl-names = "default";
		pinctrl-0 = <0x65>;
		status = "okay";
		rockchip,i2s-broken-burst-len;
		rockchip,playback-channels = <0x08>;
		rockchip,capture-channels = <0x02>;
		#sound-dai-cells = <0x00>;
		phandle = <0x91>;
	};

	iep@ff900000 {
		compatible = "rockchip,iep";
		iommu_enabled = <0x01>;
		iommus = <0x66>;
		reg = <0x00 0xff900000 0x00 0x800>;
		interrupts = <0x00 0x11 0x04>;
		clocks = <0x0a 0xca 0x0a 0x1d4>;
		clock-names = "aclk_iep\0hclk_iep";
		power-domains = <0x67 0x0c>;
		allocator = <0x01>;
		version = <0x02>;
		status = "okay";
		phandle = <0xd2>;
	};

	iommu@ff900800 {
		compatible = "rockchip,iommu";
		reg = <0x00 0xff900800 0x00 0x100>;
		interrupts = <0x00 0x11 0x04>;
		interrupt-names = "iep_mmu";
		power-domains = <0x67 0x0c>;
		#iommu-cells = <0x00>;
		status = "okay";
		phandle = <0x66>;
	};

	isp@ff910000 {
		compatible = "rockchip,rk3368-isp\0rockchip,isp";
		reg = <0x00 0xff910000 0x00 0x4000>;
		interrupts = <0x00 0x0e 0x04>;
		power-domains = <0x67 0x0c>;
		clocks = <0x0a 0xc8 0x0a 0x1d5 0x0a 0x6b 0x0a 0x6b 0x0a 0x16e 0x0a 0x84 0x0a 0x84 0x0a 0x166 0x0a 0x171 0x0a 0xcb>;
		clock-names = "aclk_isp\0hclk_isp\0clk_isp\0clk_isp_jpe\0pclkin_isp\0clk_cif_out\0clk_cif_pll\0hclk_mipiphy1\0pclk_dphyrx\0clk_vio0_noc";
		pinctrl-names = "default\0isp_dvp8bit2\0isp_dvp10bit\0isp_dvp12bit\0isp_dvp8bit0\0isp_dvp8bit4\0isp_mipi_fl\0isp_mipi_fl_prefl\0isp_flash_as_gpio\0isp_flash_as_trigger_out";
		pinctrl-0 = <0x68>;
		pinctrl-1 = <0x68 0x69>;
		pinctrl-2 = <0x68 0x69 0x6a>;
		pinctrl-3 = <0x68 0x69 0x6a 0x6b>;
		pinctrl-4 = <0x68 0x6c>;
		pinctrl-5 = <0x68 0x6d>;
		pinctrl-6 = <0x68>;
		pinctrl-7 = <0x68 0x6e>;
		pinctrl-8 = <0x6f>;
		pinctrl-9 = <0x70>;
		rockchip,isp,mipiphy = <0x02>;
		rockchip,isp,cifphy = <0x01>;
		rockchip,isp,mipiphy1,reg = <0xff964000 0x4000>;
		rockchip,isp,csiphy,reg = <0xff96c000 0x4000>;
		rockchip,grf = <0x3a>;
		rockchip,cru = <0x0a>;
		rockchip,gpios = <0x3c 0x14 0x00>;
		rockchip,isp,iommu-enable = <0x01>;
		iommus = <0x71>;
		status = "okay";
		phandle = <0xd3>;
	};

	rkisp1@ff910000 {
		compatible = "rockchip,rk3368-rkisp1";
		reg = <0x00 0xff910000 0x00 0x4000>;
		interrupts = <0x00 0x0e 0x04>;
		interrupt-names = "isp_irq";
		clocks = <0x0a 0xc8 0x0a 0x1d5 0x0a 0x6b 0x0a 0x16e>;
		clock-names = "aclk_isp\0hclk_isp\0clk_isp\0pclk_isp";
		devfreq = <0x72>;
		power-domains = <0x67 0x0c>;
		iommus = <0x71>;
		status = "disabled";
		phandle = <0xd4>;
	};

	iommu@ff914000 {
		compatible = "rockchip,iommu";
		reg = <0x00 0xff914000 0x00 0x100 0x00 0xff915000 0x00 0x100>;
		interrupts = <0x00 0x0e 0x04>;
		interrupt-names = "isp_mmu";
		clocks = <0x0a 0xc8 0x0a 0x1d5>;
		clock-names = "aclk\0hclk";
		rk_iommu,disable_reset_quirk;
		#iommu-cells = <0x00>;
		power-domains = <0x67 0x0c>;
		status = "okay";
		phandle = <0x71>;
	};

	vop@ff930000 {
		compatible = "rockchip,rk3368-vop";
		rockchip,grf = <0x3a>;
		reg = <0x00 0xff930000 0x00 0x2fc 0x00 0xff931000 0x00 0x400>;
		reg-names = "regs\0gamma_lut";
		interrupts = <0x00 0x0f 0x04>;
		clocks = <0x0a 0xc6 0x0a 0xbe 0x0a 0x1d1>;
		clock-names = "aclk_vop\0dclk_vop\0hclk_vop";
		assigned-clocks = <0x0a 0xc6 0x0a 0x1d1>;
		assigned-clock-rates = <0x17d78400 0xbebc200>;
		resets = <0x0a 0x64 0x0a 0x65 0x0a 0x66>;
		reset-names = "axi\0ahb\0dclk";
		power-domains = <0x67 0x0c>;
		iommus = <0x73>;
		status = "okay";
		phandle = <0xd5>;

		port {
			#address-cells = <0x01>;
			#size-cells = <0x00>;
			phandle = <0x79>;

			endpoint@0 {
				reg = <0x00>;
				remote-endpoint = <0x74>;
				phandle = <0x7b>;
			};

			endpoint@1 {
				reg = <0x01>;
				remote-endpoint = <0x75>;
				phandle = <0x7c>;
			};

			endpoint@2 {
				reg = <0x02>;
				remote-endpoint = <0x76>;
				phandle = <0x7d>;
			};

			endpoint@3 {
				reg = <0x03>;
				remote-endpoint = <0x77>;
				phandle = <0x5a>;
			};

			endpoint@4 {
				reg = <0x04>;
				remote-endpoint = <0x78>;
				phandle = <0x5d>;
			};
		};
	};

	display-subsystem {
		compatible = "rockchip,display-subsystem";
		ports = <0x79>;
		devfreq = <0x72>;
		status = "okay";
		logo-memory-region = <0x7a>;
		phandle = <0xd6>;

		route {

			route-dsi {
				status = "disabled";
				logo,uboot = "logo.bmp";
				logo,kernel = "logo_kernel.bmp";
				logo,mode = "center";
				charge_logo,mode = "center";
				connect = <0x7b>;
				phandle = <0xd7>;
			};

			route-edp {
				status = "disabled";
				logo,uboot = "logo.bmp";
				logo,kernel = "logo_kernel.bmp";
				logo,mode = "center";
				charge_logo,mode = "center";
				connect = <0x7c>;
				phandle = <0xd8>;
			};

			route-hdmi {
				status = "okay";
				logo,uboot = "logo.bmp";
				logo,kernel = "logo_kernel.bmp";
				logo,mode = "center";
				charge_logo,mode = "center";
				connect = <0x7d>;
				phandle = <0xd9>;
			};

			route-lvds {
				status = "disabled";
				logo,uboot = "logo.bmp";
				logo,kernel = "logo_kernel.bmp";
				logo,mode = "center";
				charge_logo,mode = "center";
				connect = <0x5a>;
				phandle = <0xda>;
			};

			route-rgb {
				status = "okay";
				logo,uboot = "logo.bmp";
				logo,kernel = "logo_kernel.bmp";
				logo,mode = "center";
				charge_logo,mode = "center";
				connect = <0x5d>;
				phandle = <0xdb>;
			};
		};
	};

	iommu@ff930300 {
		compatible = "rockchip,iommu";
		reg = <0x00 0xff930300 0x00 0x100>;
		interrupts = <0x00 0x0f 0x04>;
		interrupt-names = "vop_mmu";
		clocks = <0x0a 0xc6 0x0a 0x1d1>;
		clock-names = "aclk\0hclk";
		power-domains = <0x67 0x0c>;
		#iommu-cells = <0x00>;
		status = "okay";
		phandle = <0x73>;
	};

	cif@ff950000 {
		compatible = "rockchip,cif";
		reg = <0x00 0xff950000 0x00 0x400>;
		interrupts = <0x00 0x0d 0x04>;
		clocks = <0x0a 0x16f 0x0a 0xcc 0x0a 0x1d9 0x0a 0x83 0x0a 0x84>;
		clock-names = "pclk_cif\0aclk_cif0\0hclk_cif0\0cif0_in\0cif0_out";
		resets = <0x0a 0x68>;
		reset-names = "rst_cif";
		pinctrl-names = "cif_pin_all";
		pinctrl-0 = <0x68 0x69 0x6b>;
		rockchip,grf = <0x3a>;
		power-domains = <0x67 0x0c>;
		iommus = <0x7e>;
		status = "okay";
		phandle = <0xdc>;
	};

	iommu@ff950800 {
		compatible = "rockchip,iommu";
		reg = <0x00 0xff950800 0x00 0x100>;
		interrupts = <0x00 0x0d 0x04>;
		interrupt-names = "vip_mmu";
		clocks = <0x0a 0xcc 0x0a 0x1d9>;
		clock-names = "aclk\0hclk";
		rk_iommu,disable_reset_quirk;
		#iommu-cells = <0x00>;
		power-domains = <0x67 0x0c>;
		status = "okay";
		phandle = <0x7e>;
	};

	dsi@ff960000 {
		compatible = "rockchip,rk3368-mipi-dsi";
		reg = <0x00 0xff960000 0x00 0x4000>;
		interrupts = <0x00 0x13 0x04>;
		clocks = <0x0a 0x164 0x59>;
		clock-names = "pclk\0hs_clk";
		resets = <0x0a 0x73>;
		reset-names = "apb";
		phys = <0x59>;
		phy-names = "mipi_dphy";
		rockchip,grf = <0x3a>;
		power-domains = <0x67 0x0c>;
		#address-cells = <0x01>;
		#size-cells = <0x00>;
		status = "disabled";
		phandle = <0xdd>;

		ports {

			port {

				endpoint {
					remote-endpoint = <0x7b>;
					phandle = <0x74>;
				};
			};
		};
	};

	video-phy@ff968000 {
		compatible = "rockchip,rk3368-video-phy";
		reg = <0x00 0xff968000 0x00 0x4000 0x00 0xff960000 0x00 0x4000>;
		clocks = <0x0a 0x81 0x0a 0x172 0x0a 0x164>;
		clock-names = "ref\0pclk_phy\0pclk_host";
		#clock-cells = <0x00>;
		resets = <0x0a 0x72>;
		reset-names = "rst";
		power-domains = <0x67 0x0c>;
		#phy-cells = <0x00>;
		status = "okay";
		phandle = <0x59>;
	};

	mipi-dphy-rx0@ff96C000 {
		compatible = "rockchip,rk3368-mipi-dphy";
		reg = <0x00 0xff96c000 0x00 0x4000>;
		clocks = <0x0a 0x171>;
		clock-names = "pclk_dphyrx";
		power-domains = <0x67 0x0c>;
		rockchip,grf = <0x3a>;
		status = "disabled";
		phandle = <0xde>;
	};

	edp@ff970000 {
		compatible = "rockchip,rk3368-edp";
		reg = <0x00 0xff970000 0x00 0x8000>;
		interrupts = <0x00 0x69 0x04>;
		clocks = <0x0a 0x69 0x0a 0x163>;
		clock-names = "dp\0pclk";
		resets = <0x0a 0x7a>;
		reset-names = "dp";
		power-domains = <0x67 0x0c>;
		rockchip,grf = <0x3a>;
		phys = <0x7f>;
		phy-names = "dp";
		pinctrl-names = "default";
		pinctrl-0 = <0x80>;
		status = "disabled";
		phandle = <0xdf>;

		ports {
			#address-cells = <0x01>;
			#size-cells = <0x00>;

			port@0 {
				reg = <0x00>;
				phandle = <0xe0>;

				endpoint {
					remote-endpoint = <0x7c>;
					phandle = <0x75>;
				};
			};
		};
	};

	hdmi@ff980000 {
		compatible = "rockchip,rk3368-dw-hdmi";
		reg = <0x00 0xff980000 0x00 0x20000>;
		reg-io-width = <0x04>;
		interrupts = <0x00 0x67 0x04>;
		clocks = <0x0a 0x168 0x0a 0x6d 0x0a 0x6e>;
		clock-names = "iahb\0isfr\0cec";
		pinctrl-names = "default";
		pinctrl-0 = <0x81 0x82>;
		resets = <0x0a 0x79>;
		reset-names = "hdmi";
		power-domains = <0x67 0x0c>;
		rockchip,grf = <0x3a>;
		status = "okay";
		#sound-dai-cells = <0x00>;
		phandle = <0x93>;

		ports {

			port {

				endpoint {
					remote-endpoint = <0x7d>;
					phandle = <0x76>;
				};
			};
		};
	};

	iommu@ff9a0440 {
		compatible = "rockchip,iommu";
		reg = <0x00 0xff9a0440 0x00 0x40 0x00 0xff9a0480 0x00 0x40>;
		interrupts = <0x00 0x0c 0x04>;
		interrupt-names = "hevc_mmu";
		clocks = <0x0a 0xd0 0x0a 0x1dc>;
		clock-names = "aclk\0hclk";
		power-domains = <0x67 0x0e>;
		#iommu-cells = <0x00>;
		status = "okay";
		phandle = <0x84>;
	};

	iommu@ff9a0800 {
		compatible = "rockchip,iommu";
		reg = <0x00 0xff9a0800 0x00 0x100>;
		interrupts = <0x00 0x09 0x04 0x00 0x0a 0x04>;
		interrupt-names = "vepu_mmu\0vdpu_mmu";
		clocks = <0x0a 0xd0 0x0a 0x1dc>;
		clock-names = "aclk\0hclk";
		power-domains = <0x67 0x0e>;
		#iommu-cells = <0x00>;
		status = "okay";
		phandle = <0x83>;
	};

	vpu_service {
		compatible = "rockchip,vpu_sub";
		iommu_enabled = <0x01>;
		iommus = <0x83>;
		interrupts = <0x00 0x09 0x04 0x00 0x0a 0x04>;
		interrupt-names = "irq_enc\0irq_dec";
		dev_mode = <0x00>;
		allocator = <0x01>;
		phandle = <0x85>;
	};

	hevc_service {
		compatible = "rockchip,hevc_sub";
		iommu_enabled = <0x01>;
		iommus = <0x84>;
		interrupts = <0x00 0x0c 0x04>;
		interrupt-names = "irq_dec";
		dev_mode = <0x01>;
		allocator = <0x01>;
		phandle = <0x86>;
	};

	vpu_combo@ff9a0000 {
		compatible = "rockchip,vpu_combo";
		reg = <0x00 0xff9a0000 0x00 0x440>;
		rockchip,grf = <0x3a>;
		subcnt = <0x02>;
		rockchip,sub = <0x85 0x86>;
		clocks = <0x0a 0xd0 0x0a 0x1dc 0x0a 0x70 0x0a 0x6f>;
		clock-names = "aclk_vcodec\0hclk_vcodec\0clk_core\0clk_cabac";
		assigned-clocks = <0x0a 0x70 0x0a 0x6f>;
		assigned-clock-rates = <0x17d78400 0x17d78400>;
		resets = <0x0a 0x70 0x0a 0x71 0x0a 0x9a>;
		reset-names = "video_a\0video_h\0video";
		mode_bit = <0x0c>;
		mode_ctrl = <0x418>;
		power-domains = <0x67 0x0e>;
		status = "okay";
		phandle = <0xe1>;
	};

	interrupt-controller@ffb71000 {
		compatible = "arm,gic-400";
		interrupt-controller;
		#interrupt-cells = <0x03>;
		#address-cells = <0x00>;
		reg = <0x00 0xffb71000 0x00 0x1000 0x00 0xffb72000 0x00 0x2000 0x00 0xffb74000 0x00 0x2000 0x00 0xffb76000 0x00 0x2000>;
		interrupts = <0x01 0x09 0xff04>;
		phandle = <0x01>;
	};

	rogue-g6110@ffa30000 {
		compatible = "arm,rogue-G6110\0arm,rk3368-gpu";
		reg = <0x00 0xffa30000 0x00 0x10000>;
		clocks = <0x0a 0x40 0x0a 0xc0 0x0a 0xc1>;
		clock-names = "sclk_gpu_core\0aclk_gpu_mem\0aclk_gpu_cfg";
		interrupts = <0x00 0x08 0x04>;
		interrupt-names = "rogue-g6110-irq";
		power-domains = <0x67 0x10>;
		operating-points-v2 = <0x87>;
		#cooling-cells = <0x02>;
		logic-supply = <0x62>;
		phandle = <0x38>;

		power_model {
			compatible = "arm,mali-simple-power-model";
			voltage = <0x384>;
			frequency = <0x1f4>;
			static-power = <0x12c>;
			dynamic-power = <0x18c>;
			ts = <0x7d00 0x125c 0xffffffb0 0x02>;
			thermal-zone = "gpu-thermal";
			phandle = <0xe2>;
		};
	};

	gpu_opp_table {
		compatible = "operating-points-v2";
		opp-shared;
		phandle = <0x87>;

		opp-200000000 {
			opp-hz = <0x00 0xbebc200>;
			opp-microvolt = <0x10c8e0>;
		};

		opp-288000000 {
			opp-hz = <0x00 0x112a8800>;
			opp-microvolt = <0x10c8e0>;
		};

		opp-400000000 {
			opp-hz = <0x00 0x17d78400>;
			opp-microvolt = <0x10c8e0>;
		};

		opp-576000000 {
			opp-hz = <0x00 0x22551000>;
			opp-microvolt = <0x124f80>;
		};
	};

	nocp-peri@ffac1000 {
		compatible = "rockchip,rk3368-nocp";
		reg = <0x00 0xffac1000 0x00 0x400>;
		phandle = <0xe3>;
	};

	nocp-core@ffac1400 {
		compatible = "rockchip,rk3368-nocp";
		reg = <0x00 0xffac1400 0x00 0x400>;
		phandle = <0xe4>;
	};

	nocp-gpu@ffac1800 {
		compatible = "rockchip,rk3368-nocp";
		reg = <0x00 0xffac1800 0x00 0x400>;
		phandle = <0xe5>;
	};

	nocp-vpu@ffac2000 {
		compatible = "rockchip,rk3368-nocp";
		reg = <0x00 0xffac2000 0x00 0x400>;
		phandle = <0xe6>;
	};

	nocp-vop@ffac2400 {
		compatible = "rockchip,rk3368-nocp";
		reg = <0x00 0xffac2400 0x00 0x400>;
		phandle = <0xe7>;
	};

	nocp-rga@ffac2800 {
		compatible = "rockchip,rk3368-nocp";
		reg = <0x00 0xffac2800 0x00 0x400>;
		phandle = <0xe8>;
	};

	efuse@ffb00000 {
		compatible = "rockchip,rk3368-efuse";
		reg = <0x00 0xffb00000 0x00 0x20>;
		#address-cells = <0x01>;
		#size-cells = <0x01>;
		clocks = <0x0a 0x173>;
		clock-names = "pclk_efuse";
		phandle = <0xe9>;

		cpu-leakage@17 {
			reg = <0x17 0x01>;
			phandle = <0x14>;
		};

		temp-adjust@1f {
			reg = <0x1f 0x01>;
			phandle = <0x39>;
		};
	};

	pinctrl {
		compatible = "rockchip,rk3368-pinctrl";
		rockchip,grf = <0x3a>;
		rockchip,pmu = <0x88>;
		#address-cells = <0x02>;
		#size-cells = <0x02>;
		ranges;
		phandle = <0xea>;

		gpio0@ff750000 {
			compatible = "rockchip,gpio-bank";
			reg = <0x00 0xff750000 0x00 0x100>;
			clocks = <0x0a 0x140>;
			interrupts = <0x00 0x51 0x04>;
			gpio-controller;
			#gpio-cells = <0x02>;
			interrupt-controller;
			#interrupt-cells = <0x02>;
			phandle = <0x2e>;
		};

		gpio1@ff780000 {
			compatible = "rockchip,gpio-bank";
			reg = <0x00 0xff780000 0x00 0x100>;
			clocks = <0x0a 0x141>;
			interrupts = <0x00 0x52 0x04>;
			gpio-controller;
			#gpio-cells = <0x02>;
			interrupt-controller;
			#interrupt-cells = <0x02>;
			phandle = <0xeb>;
		};

		gpio2@ff790000 {
			compatible = "rockchip,gpio-bank";
			reg = <0x00 0xff790000 0x00 0x100>;
			clocks = <0x0a 0x142>;
			interrupts = <0x00 0x53 0x04>;
			gpio-controller;
			#gpio-cells = <0x02>;
			interrupt-controller;
			#interrupt-cells = <0x02>;
			phandle = <0x99>;
		};

		gpio3@ff7a0000 {
			compatible = "rockchip,gpio-bank";
			reg = <0x00 0xff7a0000 0x00 0x100>;
			clocks = <0x0a 0x143>;
			interrupts = <0x00 0x54 0x04>;
			gpio-controller;
			#gpio-cells = <0x02>;
			interrupt-controller;
			#interrupt-cells = <0x02>;
			phandle = <0x3c>;
		};

		pcfg-pull-up {
			bias-pull-up;
			phandle = <0x8c>;
		};

		pcfg-pull-down {
			bias-pull-down;
			phandle = <0x8e>;
		};

		pcfg-pull-none {
			bias-disable;
			phandle = <0x89>;
		};

		pcfg-pull-none-12ma {
			bias-disable;
			drive-strength = <0x0c>;
			phandle = <0x8d>;
		};

		edp {

			edp-hpd {
				rockchip,pins = <0x02 0x17 0x02 0x89>;
				phandle = <0x80>;
			};
		};

		emmc {

			emmc-clk {
				rockchip,pins = <0x02 0x04 0x02 0x8a>;
				phandle = <0x1d>;
			};

			emmc-cmd {
				rockchip,pins = <0x01 0x1a 0x02 0x8b>;
				phandle = <0x1e>;
			};

			emmc-pwr {
				rockchip,pins = <0x01 0x1b 0x02 0x8c>;
				phandle = <0xec>;
			};

			emmc-bus1 {
				rockchip,pins = <0x01 0x12 0x02 0x8c>;
				phandle = <0xed>;
			};

			emmc-bus4 {
				rockchip,pins = <0x01 0x12 0x02 0x8c 0x01 0x13 0x02 0x8c 0x01 0x14 0x02 0x8c 0x01 0x15 0x02 0x8c>;
				phandle = <0xee>;
			};

			emmc-bus8 {
				rockchip,pins = <0x01 0x12 0x02 0x8b 0x01 0x13 0x02 0x8b 0x01 0x14 0x02 0x8b 0x01 0x15 0x02 0x8b 0x01 0x16 0x02 0x8b 0x01 0x17 0x02 0x8b 0x01 0x18 0x02 0x8b 0x01 0x19 0x02 0x8b>;
				phandle = <0x1f>;
			};

			emmc-reset {
				rockchip,pins = <0x02 0x03 0x00 0x89>;
				phandle = <0xef>;
			};
		};

		gmac {

			rgmii-pins {
				rockchip,pins = <0x03 0x16 0x01 0x89 0x03 0x18 0x01 0x89 0x03 0x13 0x01 0x89 0x03 0x08 0x01 0x8d 0x03 0x09 0x01 0x8d 0x03 0x0a 0x01 0x8d 0x03 0x0e 0x01 0x8d 0x03 0x1c 0x01 0x8d 0x03 0x0d 0x01 0x8d 0x03 0x0f 0x01 0x89 0x03 0x10 0x01 0x89 0x03 0x11 0x01 0x89 0x03 0x12 0x01 0x89 0x03 0x19 0x01 0x89 0x03 0x14 0x01 0x89>;
				phandle = <0xf0>;
			};

			rmii-pins {
				rockchip,pins = <0x03 0x16 0x01 0x89 0x03 0x18 0x01 0x89 0x03 0x13 0x01 0x89 0x03 0x08 0x01 0x8d 0x03 0x09 0x01 0x8d 0x03 0x0d 0x01 0x8d 0x03 0x0f 0x01 0x89 0x03 0x10 0x01 0x89 0x03 0x14 0x01 0x89 0x03 0x15 0x01 0x89>;
				phandle = <0x3d>;
			};
		};

		hdmi {

			hdmi-cec {
				rockchip,pins = <0x03 0x17 0x01 0x89>;
				phandle = <0x82>;
			};

			hdmi-i2c-xfer {
				rockchip,pins = <0x03 0x1a 0x01 0x89 0x03 0x1b 0x01 0x89>;
				phandle = <0x81>;
			};
		};

		i2c0 {

			i2c0-xfer {
				rockchip,pins = <0x00 0x06 0x01 0x89 0x00 0x07 0x01 0x89>;
				phandle = <0x2d>;
			};
		};

		i2c1 {

			i2c1-xfer {
				rockchip,pins = <0x02 0x15 0x01 0x89 0x02 0x16 0x01 0x89>;
				phandle = <0x41>;
			};
		};

		i2c2 {

			i2c2-xfer {
				rockchip,pins = <0x00 0x09 0x02 0x89 0x03 0x1f 0x02 0x89>;
				phandle = <0x32>;
			};
		};

		i2c3 {

			i2c3-xfer {
				rockchip,pins = <0x01 0x10 0x01 0x89 0x01 0x11 0x01 0x89>;
				phandle = <0x33>;
			};
		};

		i2c4 {

			i2c4-xfer {
				rockchip,pins = <0x03 0x18 0x02 0x89 0x03 0x19 0x02 0x89>;
				phandle = <0x34>;
			};
		};

		i2c5 {

			i2c5-xfer {
				rockchip,pins = <0x03 0x1a 0x02 0x89 0x03 0x1b 0x02 0x89>;
				phandle = <0x35>;
			};
		};

		i2s {

			i2s-8ch-bus {
				rockchip,pins = <0x02 0x0c 0x01 0x89 0x02 0x0d 0x01 0x89 0x02 0x0e 0x01 0x89 0x02 0x0f 0x01 0x89 0x02 0x10 0x01 0x89 0x02 0x11 0x01 0x89 0x02 0x12 0x01 0x89 0x02 0x13 0x01 0x89>;
				phandle = <0x65>;
			};

			i2s-8ch-mclk {
				rockchip,pins = <0x02 0x14 0x01 0x89>;
				phandle = <0x42>;
			};
		};

		pwm0 {

			pwm0-pin {
				rockchip,pins = <0x03 0x08 0x02 0x89>;
				phandle = <0x45>;
			};

			pwm0-pin-pull-down {
				rockchip,pins = <0x03 0x08 0x02 0x8e>;
				phandle = <0xf1>;
			};

			vop-pwm {
				rockchip,pins = <0x03 0x08 0x03 0x89>;
				phandle = <0xf2>;
			};
		};

		pwm1 {

			pwm1-pin {
				rockchip,pins = <0x00 0x08 0x02 0x89>;
				phandle = <0x46>;
			};

			pwm1-pin-pull-down {
				rockchip,pins = <0x00 0x08 0x02 0x8e>;
				phandle = <0xf3>;
			};
		};

		pwm3 {

			pwm3-pin {
				rockchip,pins = <0x03 0x1e 0x03 0x89>;
				phandle = <0x47>;
			};

			pwm3-pin-pull-down {
				rockchip,pins = <0x03 0x1e 0x03 0x8e>;
				phandle = <0xf4>;
			};
		};

		sdio0 {

			sdio0-bus1 {
				rockchip,pins = <0x02 0x1c 0x01 0x8c>;
				phandle = <0xf5>;
			};

			sdio0-bus4 {
				rockchip,pins = <0x02 0x1c 0x01 0x8c 0x02 0x1d 0x01 0x8c 0x02 0x1e 0x01 0x8c 0x02 0x1f 0x01 0x8c>;
				phandle = <0x1a>;
			};

			sdio0-cmd {
				rockchip,pins = <0x03 0x00 0x01 0x8c>;
				phandle = <0x1b>;
			};

			sdio0-clk {
				rockchip,pins = <0x03 0x01 0x01 0x89>;
				phandle = <0x1c>;
			};

			sdio0-cd {
				rockchip,pins = <0x03 0x02 0x01 0x8c>;
				phandle = <0xf6>;
			};

			sdio0-wp {
				rockchip,pins = <0x03 0x03 0x01 0x8c>;
				phandle = <0xf7>;
			};

			sdio0-pwr {
				rockchip,pins = <0x03 0x04 0x01 0x8c>;
				phandle = <0xf8>;
			};

			sdio0-bkpwr {
				rockchip,pins = <0x03 0x05 0x01 0x8c>;
				phandle = <0xf9>;
			};

			sdio0-int {
				rockchip,pins = <0x03 0x06 0x01 0x8c>;
				phandle = <0xfa>;
			};
		};

		sdmmc {

			sdmmc-clk {
				rockchip,pins = <0x02 0x09 0x01 0x89>;
				phandle = <0x15>;
			};

			sdmmc-cmd {
				rockchip,pins = <0x02 0x0a 0x01 0x8c>;
				phandle = <0x16>;
			};

			sdmmc-cd {
				rockchip,pins = <0x02 0x0b 0x01 0x8c>;
				phandle = <0x17>;
			};

			sdmmc-bus1 {
				rockchip,pins = <0x02 0x05 0x01 0x8c>;
				phandle = <0xfb>;
			};

			sdmmc-bus4 {
				rockchip,pins = <0x02 0x05 0x01 0x8c 0x02 0x06 0x01 0x8c 0x02 0x07 0x01 0x8c 0x02 0x08 0x01 0x8c>;
				phandle = <0x18>;
			};
		};

		spdif {

			spdif-bus {
				rockchip,pins = <0x02 0x17 0x01 0x89>;
				phandle = <0x64>;
			};
		};

		spi0 {

			spi0-clk {
				rockchip,pins = <0x01 0x1d 0x02 0x8c>;
				phandle = <0x21>;
			};

			spi0-cs0 {
				rockchip,pins = <0x01 0x18 0x03 0x8c>;
				phandle = <0x24>;
			};

			spi0-cs1 {
				rockchip,pins = <0x01 0x19 0x03 0x8c>;
				phandle = <0xfc>;
			};

			spi0-tx {
				rockchip,pins = <0x01 0x17 0x03 0x8c>;
				phandle = <0x22>;
			};

			spi0-rx {
				rockchip,pins = <0x01 0x16 0x03 0x8c>;
				phandle = <0x23>;
			};
		};

		spi1 {

			spi1-clk {
				rockchip,pins = <0x01 0x0e 0x02 0x8c>;
				phandle = <0x25>;
			};

			spi1-cs0 {
				rockchip,pins = <0x01 0x0f 0x02 0x8c>;
				phandle = <0x28>;
			};

			spi1-cs1 {
				rockchip,pins = <0x03 0x1c 0x02 0x8c>;
				phandle = <0xfd>;
			};

			spi1-rx {
				rockchip,pins = <0x01 0x10 0x02 0x8c>;
				phandle = <0x27>;
			};

			spi1-tx {
				rockchip,pins = <0x01 0x11 0x02 0x8c>;
				phandle = <0x26>;
			};
		};

		spi2 {

			spi2-clk {
				rockchip,pins = <0x00 0x0c 0x02 0x8c>;
				phandle = <0x29>;
			};

			spi2-cs0 {
				rockchip,pins = <0x00 0x0d 0x02 0x8c>;
				phandle = <0x2c>;
			};

			spi2-rx {
				rockchip,pins = <0x00 0x0a 0x02 0x8c>;
				phandle = <0x2b>;
			};

			spi2-tx {
				rockchip,pins = <0x00 0x0b 0x02 0x8c>;
				phandle = <0x2a>;
			};
		};

		uart0 {

			uart0-xfer {
				rockchip,pins = <0x02 0x18 0x01 0x8c 0x02 0x19 0x01 0x89>;
				phandle = <0xfe>;
			};

			uart0-cts {
				rockchip,pins = <0x02 0x1a 0x01 0x89>;
				phandle = <0xff>;
			};

			uart0-rts {
				rockchip,pins = <0x02 0x1b 0x01 0x89>;
				phandle = <0x9a>;
			};
		};

		uart1 {

			uart1-xfer {
				rockchip,pins = <0x00 0x14 0x03 0x8c 0x00 0x15 0x03 0x89>;
				phandle = <0x100>;
			};

			uart1-cts {
				rockchip,pins = <0x00 0x16 0x03 0x89>;
				phandle = <0x101>;
			};

			uart1-rts {
				rockchip,pins = <0x00 0x17 0x03 0x89>;
				phandle = <0x102>;
			};
		};

		uart2 {

			uart2-xfer {
				rockchip,pins = <0x02 0x06 0x02 0x8c 0x02 0x05 0x02 0x89>;
				phandle = <0x48>;
			};
		};

		uart3 {

			uart3-xfer {
				rockchip,pins = <0x03 0x1d 0x02 0x8c 0x03 0x1e 0x02 0x89>;
				phandle = <0x103>;
			};

			uart3-cts {
				rockchip,pins = <0x03 0x10 0x02 0x89>;
				phandle = <0x104>;
			};

			uart3-rts {
				rockchip,pins = <0x03 0x11 0x02 0x89>;
				phandle = <0x105>;
			};
		};

		uart4 {

			uart4-xfer {
				rockchip,pins = <0x00 0x1b 0x03 0x8c 0x00 0x1a 0x03 0x89>;
				phandle = <0x106>;
			};

			uart4-cts {
				rockchip,pins = <0x00 0x18 0x03 0x89>;
				phandle = <0x107>;
			};

			uart4-rts {
				rockchip,pins = <0x00 0x19 0x03 0x89>;
				phandle = <0x108>;
			};
		};

		isp {

			cif-clkout {
				rockchip,pins = <0x01 0x0b 0x01 0x89>;
				phandle = <0x68>;
			};

			isp-dvp-d2d9 {
				rockchip,pins = <0x01 0x00 0x01 0x89 0x01 0x01 0x01 0x89 0x01 0x02 0x01 0x89 0x01 0x03 0x01 0x89 0x01 0x04 0x01 0x89 0x01 0x05 0x01 0x89 0x01 0x06 0x01 0x89 0x01 0x07 0x01 0x89 0x01 0x08 0x01 0x89 0x01 0x09 0x01 0x89 0x01 0x0a 0x01 0x89>;
				phandle = <0x69>;
			};

			isp-dvp-d0d1 {
				rockchip,pins = <0x01 0x0c 0x01 0x89 0x01 0x0d 0x01 0x89>;
				phandle = <0x6a>;
			};

			isp_d10d11 {
				rockchip,pins = <0x01 0x0e 0x01 0x89 0x01 0x0f 0x01 0x89>;
				phandle = <0x6b>;
			};

			isp-dvp-d0d7 {
				rockchip,pins = <0x01 0x0c 0x01 0x89 0x01 0x0d 0x01 0x89 0x01 0x00 0x01 0x89 0x01 0x01 0x01 0x89 0x01 0x02 0x01 0x89 0x01 0x03 0x01 0x89 0x01 0x04 0x01 0x89 0x01 0x05 0x01 0x89>;
				phandle = <0x6c>;
			};

			isp-dvp-d4d11 {
				rockchip,pins = <0x01 0x02 0x01 0x89 0x01 0x03 0x01 0x89 0x01 0x04 0x01 0x89 0x01 0x05 0x01 0x89 0x01 0x06 0x01 0x89 0x01 0x07 0x01 0x89 0x01 0x0e 0x01 0x89 0x01 0x11 0x01 0x89>;
				phandle = <0x6d>;
			};

			isp-shutter {
				rockchip,pins = <0x03 0x13 0x02 0x89 0x03 0x16 0x02 0x89>;
				phandle = <0x109>;
			};

			isp-flash-trigger {
				rockchip,pins = <0x03 0x14 0x02 0x89>;
				phandle = <0x70>;
			};

			isp-prelight {
				rockchip,pins = <0x03 0x15 0x02 0x89>;
				phandle = <0x6e>;
			};

			isp_flash_trigger_as_gpio {
				rockchip,pins = <0x03 0x14 0x00 0x89>;
				phandle = <0x6f>;
			};
		};

		lcdc {

			lcdc-rgb-pins {
				rockchip,pins = <0x00 0x0e 0x01 0x89 0x00 0x0f 0x01 0x89 0x00 0x10 0x01 0x89 0x00 0x11 0x01 0x89 0x00 0x12 0x01 0x89 0x00 0x13 0x01 0x89 0x00 0x14 0x01 0x89 0x00 0x15 0x01 0x89 0x00 0x16 0x01 0x89 0x00 0x17 0x01 0x89 0x00 0x18 0x01 0x89 0x00 0x19 0x01 0x89 0x00 0x1a 0x01 0x89 0x00 0x1b 0x01 0x89 0x00 0x1f 0x01 0x89 0x00 0x1e 0x01 0x89 0x00 0x1c 0x01 0x89 0x00 0x1d 0x01 0x89>;
				phandle = <0x5b>;
			};

			lcdc-sleep-pins {
				rockchip,pins = <0x00 0x0e 0x00 0x89 0x00 0x0f 0x00 0x89 0x00 0x10 0x00 0x89 0x00 0x11 0x00 0x89 0x00 0x12 0x00 0x89 0x00 0x13 0x00 0x89 0x00 0x14 0x00 0x89 0x00 0x15 0x00 0x89 0x00 0x16 0x00 0x89 0x00 0x17 0x00 0x89 0x00 0x18 0x00 0x89 0x00 0x19 0x00 0x89 0x00 0x1a 0x00 0x89 0x00 0x1b 0x00 0x89 0x00 0x1f 0x00 0x89 0x00 0x1e 0x00 0x89 0x00 0x1c 0x00 0x89 0x00 0x1d 0x00 0x89>;
				phandle = <0x5c>;
			};
		};

		pcfg-pull-none-drv-8ma {
			bias-disable;
			drive-strength = <0x08>;
			phandle = <0x8a>;
		};

		pcfg-pull-up-drv-8ma {
			bias-pull-up;
			drive-strength = <0x08>;
			phandle = <0x8b>;
		};

		pmic {

			pmic-int {
				rockchip,pins = <0x00 0x05 0x00 0x8c>;
				phandle = <0x2f>;
			};
		};

		keys {

			pwr-key {
				rockchip,pins = <0x00 0x02 0x00 0x8c>;
				phandle = <0x94>;
			};
		};

		leds {

			stby-pwren {
				rockchip,pins = <0x00 0x0c 0x00 0x89>;
				phandle = <0x10a>;
			};

			led-ctl {
				rockchip,pins = <0x03 0x1d 0x00 0x89>;
				phandle = <0x95>;
			};
		};

		sdio-pwrseq {

			wifi-enable-h {
				rockchip,pins = <0x03 0x04 0x00 0x89>;
				phandle = <0x98>;
			};
		};

		wireless-bluetooth {

			uart0-gpios {
				rockchip,pins = <0x02 0x1b 0x00 0x89>;
				phandle = <0x9b>;
			};
		};

		usb {

			host-vbus-drv {
				rockchip,pins = <0x00 0x04 0x00 0x89>;
				phandle = <0x96>;
			};
		};
	};

	rockchip-suspend {
		compatible = "rockchip,pm-rk3368";
		status = "okay";
		rockchip,sleep-debug-en = <0x01>;
		rockchip,sleep-mode-config = <0x80104>;
		rockchip,wakeup-config = <0x85>;
		phandle = <0x10b>;
	};

	chosen {
		bootargs = "earlycon=uart8250,mmio32,0xff690000 swiotlb=1 firmware_class.path=/system/vendor/firmware";
		phandle = <0x10c>;
	};

	fiq-debugger {
		compatible = "rockchip,fiq-debugger";
		rockchip,serial-id = <0x02>;
		rockchip,wake-irq = <0x00>;
		rockchip,irq-mode-enable = <0x00>;
		rockchip,baudrate = <0x1c200>;
		pinctrl-names = "default";
		pinctrl-0 = <0x48>;
		interrupts = <0x00 0x9a 0x04>;
		phandle = <0x10d>;
	};

	ramoops_mem {
		reg = <0x00 0x110000 0x00 0xf0000>;
		reg-names = "ramoops_mem";
		phandle = <0x8f>;
	};

	ramoops {
		compatible = "ramoops";
		record-size = <0x00 0x20000>;
		console-size = <0x00 0x80000>;
		ftrace-size = <0x00 0x00>;
		pmsg-size = <0x00 0x50000>;
		memory-region = <0x8f>;
	};

	reserved-memory {
		#address-cells = <0x02>;
		#size-cells = <0x02>;
		ranges;

		drm-logo@00000000 {
			compatible = "rockchip,drm-logo";
			reg = <0x00 0x00 0x00 0x00>;
			phandle = <0x7a>;
		};

		linux,cma {
			compatible = "shared-dma-pool";
			reusable;
			size = <0x00 0x2000000>;
			linux,cma-default;
		};
	};

	ion {
		compatible = "rockchip,ion";
		#address-cells = <0x01>;
		#size-cells = <0x00>;

		cma-heap {
			reg = <0x00 0x2800000>;
		};

		system-heap {
		};
	};

	firmware {

		android {
			compatible = "android,firmware";
			boot_devices = "ff0f0000.dwmmc,ff400000.nandc";
			phandle = <0x10e>;

			vbmeta {
				compatible = "android,vbmeta";
				parts = "vbmeta,dtbo";
			};

			fstab {
				compatible = "android,fstab";

				vendor {
					compatible = "android,vendor";
					dev = "/dev/block/by-name/vendor";
					type = "ext4";
					mnt_flags = "ro,barrier=1,inode_readahead_blks=8";
					fsmgr_flags = "wait,avb";
				};
			};
		};
	};

	rga@ff920000 {
		compatible = "rockchip,rga2";
		dev_mode = <0x01>;
		reg = <0x00 0xff920000 0x00 0x1000>;
		interrupts = <0x00 0x12 0x04>;
		clocks = <0x0a 0xc8 0x0a 0x1d6 0x0a 0x6a>;
		clock-names = "aclk_rga\0hclk_rga\0clk_rga";
		dma-coherent;
		status = "okay";
	};

	dwc-control-usb {
		compatible = "rockchip,rk3368-dwc-control-usb";
		status = "okay";
		rockchip,grf = <0x3a>;
		grf-offset = <0x4bc>;
		interrupts = <0x00 0x5d 0x04 0x00 0x5e 0x04 0x00 0x5f 0x04 0x00 0x60 0x04>;
		interrupt-names = "otg_id\0otg_bvalid\0otg_linestate\0host0_linestate";
		clocks = <0x0a 0x1bf>;
		clock-names = "hclk_usb_peri";
		otg_drv_gpio = <0x2e 0x19 0x01>;
		rockchip,remote_wakeup;
		rockchip,usb_irq_wakeup;
		phandle = <0x10f>;

		usb_bc {
			compatible = "inno,phy";
			regbase = "/dwc-control-usb";
			rk_usb,bvalid = <0x4bc 0x17 0x01>;
			rk_usb,iddig = <0x4bc 0x1a 0x01>;
			rk_usb,vdmsrcen = <0x718 0x0c 0x01>;
			rk_usb,vdpsrcen = <0x718 0x0b 0x01>;
			rk_usb,rdmpden = <0x718 0x0a 0x01>;
			rk_usb,idpsrcen = <0x718 0x09 0x01>;
			rk_usb,idmsinken = <0x718 0x08 0x01>;
			rk_usb,idpsinken = <0x718 0x07 0x01>;
			rk_usb,dpattach = <0x4b8 0x1f 0x01>;
			rk_usb,cpdet = <0x4b8 0x1e 0x01>;
			rk_usb,dcpattach = <0x4b8 0x1d 0x01>;
		};
	};

	xin32k {
		status = "okay";
		compatible = "pwm-clock";
		#clock-cells = <0x00>;
		clock-frequency = <0x8000>;
		clock-output-names = "xin32k";
		pwms = <0x90 0x00 0x7736 0x00>;
		phandle = <0x110>;
	};

	sound {
		compatible = "rockchip,rk3368-hdmi-analog";
		rockchip,cpu = <0x91>;
		rockchip,codec = <0x92 0x93>;
	};

	gpio-keys {
		compatible = "gpio-keys";
		#address-cells = <0x01>;
		#size-cells = <0x00>;
		pinctrl-names = "default";
		pinctrl-0 = <0x94>;
		phandle = <0x111>;

		button@0 {
			gpio-key,wakeup = <0x01>;
			gpios = <0x2e 0x02 0x01>;
			label = "GPIO Power";
			linux,code = <0x74>;
		};
	};

	gpio-leds {
		compatible = "gpio-leds";
		phandle = <0x112>;

		work {
			gpios = <0x3c 0x1d 0x00>;
			label = "r88:green:led";
			pinctrl-names = "default";
			pinctrl-0 = <0x95>;
		};
	};

	vcc-sys {
		compatible = "regulator-fixed";
		regulator-name = "vcc_sys";
		regulator-always-on;
		regulator-boot-on;
		regulator-min-microvolt = <0x39fbc0>;
		regulator-max-microvolt = <0x39fbc0>;
		phandle = <0x30>;
	};

	vcc-host {
		compatible = "regulator-fixed";
		enable-active-high;
		gpio = <0x2e 0x04 0x00>;
		pinctrl-names = "default";
		pinctrl-0 = <0x96>;
		regulator-name = "vcc_host";
		regulator-always-on;
		phandle = <0x113>;
	};

	vcc-phy-regulator {
		compatible = "regulator-fixed";
		regulator-name = "vcc_phy";
		regulator-always-on;
		regulator-boot-on;
		phandle = <0x3b>;
	};

	gmac-clk {
		compatible = "fixed-clock";
		clock-frequency = <0x7735940>;
		clock-output-names = "ext_gmac";
		#clock-cells = <0x00>;
		phandle = <0x114>;
	};

	sdio-pwrseq {
		compatible = "mmc-pwrseq-simple";
		clocks = <0x97 0x01>;
		clock-names = "ext_clock";
		pinctrl-names = "default";
		pinctrl-0 = <0x98>;
		reset-gpios = <0x3c 0x04 0x01>;
		phandle = <0x19>;
	};

	wireless-wlan {
		compatible = "wlan-platdata";
		rockchip,grf = <0x3a>;
		wifi_chip_type = "rtl8189es";
		sdio_vref = <0x708>;
		WIFI,host_wake_irq = <0x3c 0x06 0x00>;
		status = "okay";
	};

	wireless-bluetooth {
		compatible = "bluetooth-platdata";
		clocks = <0x97 0x01>;
		clock-names = "ext_clock";
		uart_rts_gpios = <0x99 0x1b 0x01>;
		pinctrl-names = "default\0rts_gpio";
		pinctrl-0 = <0x9a>;
		pinctrl-1 = <0x9b>;
		BT,reset_gpio = <0x3c 0x05 0x00>;
		BT,wake_gpio = <0x3c 0x02 0x00>;
		BT,wake_host_irq = <0x3c 0x07 0x00>;
		status = "okay";
	};

	__symbols__ {
		ddr_timing = "/ddr_timing";
		cpu_l0 = "/cpus/cpu@0";
		cpu_l1 = "/cpus/cpu@1";
		cpu_l2 = "/cpus/cpu@2";
		cpu_l3 = "/cpus/cpu@3";
		cpu_b0 = "/cpus/cpu@100";
		cpu_b1 = "/cpus/cpu@101";
		cpu_b2 = "/cpus/cpu@102";
		cpu_b3 = "/cpus/cpu@103";
		cluster0_l2 = "/cpus/l2-cache0";
		cluster1_l2 = "/cpus/l2-cache1";
		cluster0_opp = "/opp_table0";
		cluster1_opp = "/opp_table1";
		RK3368_CPU_COST_0 = "/energy-costs/rk3368-core-cost0";
		RK3368_CPU_COST_1 = "/energy-costs/rk3368-core-cost1";
		RK3368_CLUSTER_COST_0 = "/energy-costs/rk3368-cluster-cost0";
		RK3368_CLUSTER_COST_1 = "/energy-costs/rk3368-cluster-cost1";
		dmac_peri = "/amba/dma-controller@ff250000";
		dmac_bus = "/amba/dma-controller@ff600000";
		xin24m = "/oscillator";
		sdmmc = "/dwmmc@ff0c0000";
		sdio0 = "/dwmmc@ff0d0000";
		emmc = "/dwmmc@ff0f0000";
		saradc = "/saradc@ff100000";
		spi0 = "/spi@ff110000";
		spi1 = "/spi@ff120000";
		spi2 = "/spi@ff130000";
		i2c0 = "/i2c@ff650000";
		rk808 = "/i2c@ff650000/pmic@1b";
		vdd_cpu = "/i2c@ff650000/pmic@1b/regulators/DCDC_REG1";
		vdd_gpu = "/i2c@ff650000/pmic@1b/regulators/DCDC_REG2";
		vcc_ddr = "/i2c@ff650000/pmic@1b/regulators/DCDC_REG3";
		vcc_io = "/i2c@ff650000/pmic@1b/regulators/DCDC_REG4";
		vcc18_flash = "/i2c@ff650000/pmic@1b/regulators/LDO_REG1";
		vcca_33 = "/i2c@ff650000/pmic@1b/regulators/LDO_REG2";
		vdd_10 = "/i2c@ff650000/pmic@1b/regulators/LDO_REG3";
		vcca_18 = "/i2c@ff650000/pmic@1b/regulators/LDO_REG4";
		vccio_sd = "/i2c@ff650000/pmic@1b/regulators/LDO_REG5";
		vdd10_lcd = "/i2c@ff650000/pmic@1b/regulators/LDO_REG6";
		vcc_18 = "/i2c@ff650000/pmic@1b/regulators/LDO_REG7";
		vcc18_lcd = "/i2c@ff650000/pmic@1b/regulators/LDO_REG8";
		vcc_sd = "/i2c@ff650000/pmic@1b/regulators/SWITCH_REG1";
		vcc_lan = "/i2c@ff650000/pmic@1b/regulators/SWITCH_REG2";
		hym8563 = "/i2c@ff650000/hym8563@51";
		i2c2 = "/i2c@ff140000";
		i2c3 = "/i2c@ff150000";
		i2c4 = "/i2c@ff160000";
		i2c5 = "/i2c@ff170000";
		uart0 = "/serial@ff180000";
		uart1 = "/serial@ff190000";
		uart3 = "/serial@ff1b0000";
		uart4 = "/serial@ff1c0000";
		thermal_zones = "/thermal-zones";
		soc_thermal = "/thermal-zones/soc-thermal";
		threshold = "/thermal-zones/soc-thermal/trips/trip-point-0";
		target = "/thermal-zones/soc-thermal/trips/trip-point-1";
		soc_crit = "/thermal-zones/soc-thermal/trips/soc-crit";
		gpu_thermal = "/thermal-zones/gpu-thermal";
		tsadc = "/tsadc@ff280000";
		gmac = "/ethernet@ff290000";
		nandc0 = "/nandc@ff400000";
		usb_host0_ehci = "/usb@ff500000";
		usb_host0_ohci = "/usb@ff520000";
		usb_otg = "/usb@ff580000";
		ddrpctl = "/syscon@ff610000";
		i2c1 = "/i2c@ff660000";
		rk1000_ctl = "/i2c@ff660000/rk1000-ctl@40";
		tve_in_rgb = "/i2c@ff660000/rk1000-tve@42/port@0/endpoint";
		rk1000_codec = "/i2c@ff660000/rk1000-codec@60";
		pwm0 = "/pwm@ff680000";
		pwm1 = "/pwm@ff680010";
		pwm2 = "/pwm@ff680020";
		pwm3 = "/pwm@ff680030";
		uart2 = "/serial@ff690000";
		mbox = "/mbox@ff6b0000";
		mailbox = "/mailbox@ff6b0000";
		mailbox_scpi = "/mailbox-scpi";
		qos_iep = "/qos@ffad0000";
		qos_isp_r0 = "/qos@ffad0080";
		qos_isp_r1 = "/qos@ffad0100";
		qos_isp_w0 = "/qos@ffad0180";
		qos_isp_w1 = "/qos@ffad0200";
		qos_vip = "/qos@ffad0280";
		qos_vop = "/qos@ffad0300";
		qos_rga_r = "/qos@ffad0380";
		qos_rga_w = "/qos@ffad0400";
		qos_hevc_r = "/qos@ffae0000";
		qos_vpu_r = "/qos@ffae0100";
		qos_vpu_w = "/qos@ffae0180";
		qos_gpu = "/qos@ffaf0000";
		pmu = "/power-management@ff730000";
		power = "/power-management@ff730000/power-controller";
		pmugrf = "/syscon@ff738000";
		pmu_io_domains = "/syscon@ff738000/io-domains";
		pvtm_clock = "/syscon@ff738000/pvtm-clock";
		cru = "/clock-controller@ff760000";
		grf = "/syscon@ff770000";
		edp_phy = "/syscon@ff770000/edp-phy";
		io_domains = "/syscon@ff770000/io-domains";
		lvds = "/syscon@ff770000/lvds";
		lvds_in_vop = "/syscon@ff770000/lvds/ports/port@0/endpoint";
		rgb = "/syscon@ff770000/rgb";
		rgb_in_vop = "/syscon@ff770000/rgb/ports/port@0/endpoint";
		rgb_out_tve = "/syscon@ff770000/rgb/ports/port@1/endpoint";
		u2phy = "/syscon@ff770000/usb2-phy@700";
		u2phy_otg = "/syscon@ff770000/usb2-phy@700/otg-port";
		u2phy_host = "/syscon@ff770000/usb2-phy@700/host-port";
		dfi = "/syscon@ff770000/dfi";
		dmc = "/dmc";
		dmc_opp_table = "/opp_table2";
		wdt = "/watchdog@ff800000";
		spdif = "/spdif@ff880000";
		i2s_2ch = "/i2s-2ch@ff890000";
		i2s_8ch = "/i2s-8ch@ff898000";
		iep = "/iep@ff900000";
		iep_mmu = "/iommu@ff900800";
		isp = "/isp@ff910000";
		rkisp1 = "/rkisp1@ff910000";
		isp_mmu = "/iommu@ff914000";
		vop = "/vop@ff930000";
		vop_out = "/vop@ff930000/port";
		vop_out_dsi = "/vop@ff930000/port/endpoint@0";
		vop_out_edp = "/vop@ff930000/port/endpoint@1";
		vop_out_hdmi = "/vop@ff930000/port/endpoint@2";
		vop_out_lvds = "/vop@ff930000/port/endpoint@3";
		vop_out_rgb = "/vop@ff930000/port/endpoint@4";
		display_subsystem = "/display-subsystem";
		route_dsi = "/display-subsystem/route/route-dsi";
		route_edp = "/display-subsystem/route/route-edp";
		route_hdmi = "/display-subsystem/route/route-hdmi";
		route_lvds = "/display-subsystem/route/route-lvds";
		route_rgb = "/display-subsystem/route/route-rgb";
		vop_mmu = "/iommu@ff930300";
		cif = "/cif@ff950000";
		vip_mmu = "/iommu@ff950800";
		dsi = "/dsi@ff960000";
		dsi_in_vop = "/dsi@ff960000/ports/port/endpoint";
		video_phy = "/video-phy@ff968000";
		mipi_dphy_rx0 = "/mipi-dphy-rx0@ff96C000";
		edp = "/edp@ff970000";
		edp_in = "/edp@ff970000/ports/port@0";
		edp_in_vop = "/edp@ff970000/ports/port@0/endpoint";
		hdmi = "/hdmi@ff980000";
		hdmi_in_vop = "/hdmi@ff980000/ports/port/endpoint";
		hevc_mmu = "/iommu@ff9a0440";
		vpu_mmu = "/iommu@ff9a0800";
		vpu = "/vpu_service";
		hevc = "/hevc_service";
		vpu_combo = "/vpu_combo@ff9a0000";
		gic = "/interrupt-controller@ffb71000";
		gpu = "/rogue-g6110@ffa30000";
		gpu_power_model = "/rogue-g6110@ffa30000/power_model";
		gpu_opp_table = "/gpu_opp_table";
		nocp_peri = "/nocp-peri@ffac1000";
		nocp_core = "/nocp-core@ffac1400";
		nocp_gpu = "/nocp-gpu@ffac1800";
		nocp_vpu = "/nocp-vpu@ffac2000";
		nocp_vop = "/nocp-vop@ffac2400";
		nocp_rga = "/nocp-rga@ffac2800";
		efuse = "/efuse@ffb00000";
		cpu_leakage = "/efuse@ffb00000/cpu-leakage@17";
		temp_adjust = "/efuse@ffb00000/temp-adjust@1f";
		pinctrl = "/pinctrl";
		gpio0 = "/pinctrl/gpio0@ff750000";
		gpio1 = "/pinctrl/gpio1@ff780000";
		gpio2 = "/pinctrl/gpio2@ff790000";
		gpio3 = "/pinctrl/gpio3@ff7a0000";
		pcfg_pull_up = "/pinctrl/pcfg-pull-up";
		pcfg_pull_down = "/pinctrl/pcfg-pull-down";
		pcfg_pull_none = "/pinctrl/pcfg-pull-none";
		pcfg_pull_none_12ma = "/pinctrl/pcfg-pull-none-12ma";
		edp_hpd = "/pinctrl/edp/edp-hpd";
		emmc_clk = "/pinctrl/emmc/emmc-clk";
		emmc_cmd = "/pinctrl/emmc/emmc-cmd";
		emmc_pwr = "/pinctrl/emmc/emmc-pwr";
		emmc_bus1 = "/pinctrl/emmc/emmc-bus1";
		emmc_bus4 = "/pinctrl/emmc/emmc-bus4";
		emmc_bus8 = "/pinctrl/emmc/emmc-bus8";
		emmc_reset = "/pinctrl/emmc/emmc-reset";
		rgmii_pins = "/pinctrl/gmac/rgmii-pins";
		rmii_pins = "/pinctrl/gmac/rmii-pins";
		hdmi_cec = "/pinctrl/hdmi/hdmi-cec";
		hdmi_i2c_xfer = "/pinctrl/hdmi/hdmi-i2c-xfer";
		i2c0_xfer = "/pinctrl/i2c0/i2c0-xfer";
		i2c1_xfer = "/pinctrl/i2c1/i2c1-xfer";
		i2c2_xfer = "/pinctrl/i2c2/i2c2-xfer";
		i2c3_xfer = "/pinctrl/i2c3/i2c3-xfer";
		i2c4_xfer = "/pinctrl/i2c4/i2c4-xfer";
		i2c5_xfer = "/pinctrl/i2c5/i2c5-xfer";
		i2s_8ch_bus = "/pinctrl/i2s/i2s-8ch-bus";
		i2s_8ch_mclk = "/pinctrl/i2s/i2s-8ch-mclk";
		pwm0_pin = "/pinctrl/pwm0/pwm0-pin";
		pwm0_pin_pull_down = "/pinctrl/pwm0/pwm0-pin-pull-down";
		vop_pwm_pin = "/pinctrl/pwm0/vop-pwm";
		pwm1_pin = "/pinctrl/pwm1/pwm1-pin";
		pwm1_pin_pull_down = "/pinctrl/pwm1/pwm1-pin-pull-down";
		pwm3_pin = "/pinctrl/pwm3/pwm3-pin";
		pwm3_pin_pull_down = "/pinctrl/pwm3/pwm3-pin-pull-down";
		sdio0_bus1 = "/pinctrl/sdio0/sdio0-bus1";
		sdio0_bus4 = "/pinctrl/sdio0/sdio0-bus4";
		sdio0_cmd = "/pinctrl/sdio0/sdio0-cmd";
		sdio0_clk = "/pinctrl/sdio0/sdio0-clk";
		sdio0_cd = "/pinctrl/sdio0/sdio0-cd";
		sdio0_wp = "/pinctrl/sdio0/sdio0-wp";
		sdio0_pwr = "/pinctrl/sdio0/sdio0-pwr";
		sdio0_bkpwr = "/pinctrl/sdio0/sdio0-bkpwr";
		sdio0_int = "/pinctrl/sdio0/sdio0-int";
		sdmmc_clk = "/pinctrl/sdmmc/sdmmc-clk";
		sdmmc_cmd = "/pinctrl/sdmmc/sdmmc-cmd";
		sdmmc_cd = "/pinctrl/sdmmc/sdmmc-cd";
		sdmmc_bus1 = "/pinctrl/sdmmc/sdmmc-bus1";
		sdmmc_bus4 = "/pinctrl/sdmmc/sdmmc-bus4";
		spdif_bus = "/pinctrl/spdif/spdif-bus";
		spi0_clk = "/pinctrl/spi0/spi0-clk";
		spi0_cs0 = "/pinctrl/spi0/spi0-cs0";
		spi0_cs1 = "/pinctrl/spi0/spi0-cs1";
		spi0_tx = "/pinctrl/spi0/spi0-tx";
		spi0_rx = "/pinctrl/spi0/spi0-rx";
		spi1_clk = "/pinctrl/spi1/spi1-clk";
		spi1_cs0 = "/pinctrl/spi1/spi1-cs0";
		spi1_cs1 = "/pinctrl/spi1/spi1-cs1";
		spi1_rx = "/pinctrl/spi1/spi1-rx";
		spi1_tx = "/pinctrl/spi1/spi1-tx";
		spi2_clk = "/pinctrl/spi2/spi2-clk";
		spi2_cs0 = "/pinctrl/spi2/spi2-cs0";
		spi2_rx = "/pinctrl/spi2/spi2-rx";
		spi2_tx = "/pinctrl/spi2/spi2-tx";
		uart0_xfer = "/pinctrl/uart0/uart0-xfer";
		uart0_cts = "/pinctrl/uart0/uart0-cts";
		uart0_rts = "/pinctrl/uart0/uart0-rts";
		uart1_xfer = "/pinctrl/uart1/uart1-xfer";
		uart1_cts = "/pinctrl/uart1/uart1-cts";
		uart1_rts = "/pinctrl/uart1/uart1-rts";
		uart2_xfer = "/pinctrl/uart2/uart2-xfer";
		uart3_xfer = "/pinctrl/uart3/uart3-xfer";
		uart3_cts = "/pinctrl/uart3/uart3-cts";
		uart3_rts = "/pinctrl/uart3/uart3-rts";
		uart4_xfer = "/pinctrl/uart4/uart4-xfer";
		uart4_cts = "/pinctrl/uart4/uart4-cts";
		uart4_rts = "/pinctrl/uart4/uart4-rts";
		cif_clkout = "/pinctrl/isp/cif-clkout";
		isp_dvp_d2d9 = "/pinctrl/isp/isp-dvp-d2d9";
		isp_dvp_d0d1 = "/pinctrl/isp/isp-dvp-d0d1";
		isp_dvp_d10d11 = "/pinctrl/isp/isp_d10d11";
		isp_dvp_d0d7 = "/pinctrl/isp/isp-dvp-d0d7";
		isp_dvp_d4d11 = "/pinctrl/isp/isp-dvp-d4d11";
		isp_shutter = "/pinctrl/isp/isp-shutter";
		isp_flash_trigger = "/pinctrl/isp/isp-flash-trigger";
		isp_prelight = "/pinctrl/isp/isp-prelight";
		isp_flash_trigger_as_gpio = "/pinctrl/isp/isp_flash_trigger_as_gpio";
		lcdc_rgb_pins = "/pinctrl/lcdc/lcdc-rgb-pins";
		lcdc_sleep_pins = "/pinctrl/lcdc/lcdc-sleep-pins";
		pcfg_pull_none_drv_8ma = "/pinctrl/pcfg-pull-none-drv-8ma";
		pcfg_pull_up_drv_8ma = "/pinctrl/pcfg-pull-up-drv-8ma";
		pmic_int = "/pinctrl/pmic/pmic-int";
		pwr_key = "/pinctrl/keys/pwr-key";
		stby_pwren = "/pinctrl/leds/stby-pwren";
		led_ctl = "/pinctrl/leds/led-ctl";
		wifi_enable_h = "/pinctrl/sdio-pwrseq/wifi-enable-h";
		uart0_gpios = "/pinctrl/wireless-bluetooth/uart0-gpios";
		host_vbus_drv = "/pinctrl/usb/host-vbus-drv";
		rockchip_suspend = "/rockchip-suspend";
		chosen = "/chosen";
		fiq_debugger = "/fiq-debugger";
		ramoops_mem = "/ramoops_mem";
		drm_logo = "/reserved-memory/drm-logo@00000000";
		firmware_android = "/firmware/android";
		dwc_control_usb = "/dwc-control-usb";
		xin32k = "/xin32k";
		keys = "/gpio-keys";
		leds = "/gpio-leds";
		vcc_sys = "/vcc-sys";
		vcc_host = "/vcc-host";
		vcc_phy = "/vcc-phy-regulator";
		ext_gmac = "/gmac-clk";
		sdio_pwrseq = "/sdio-pwrseq";
	};
};
